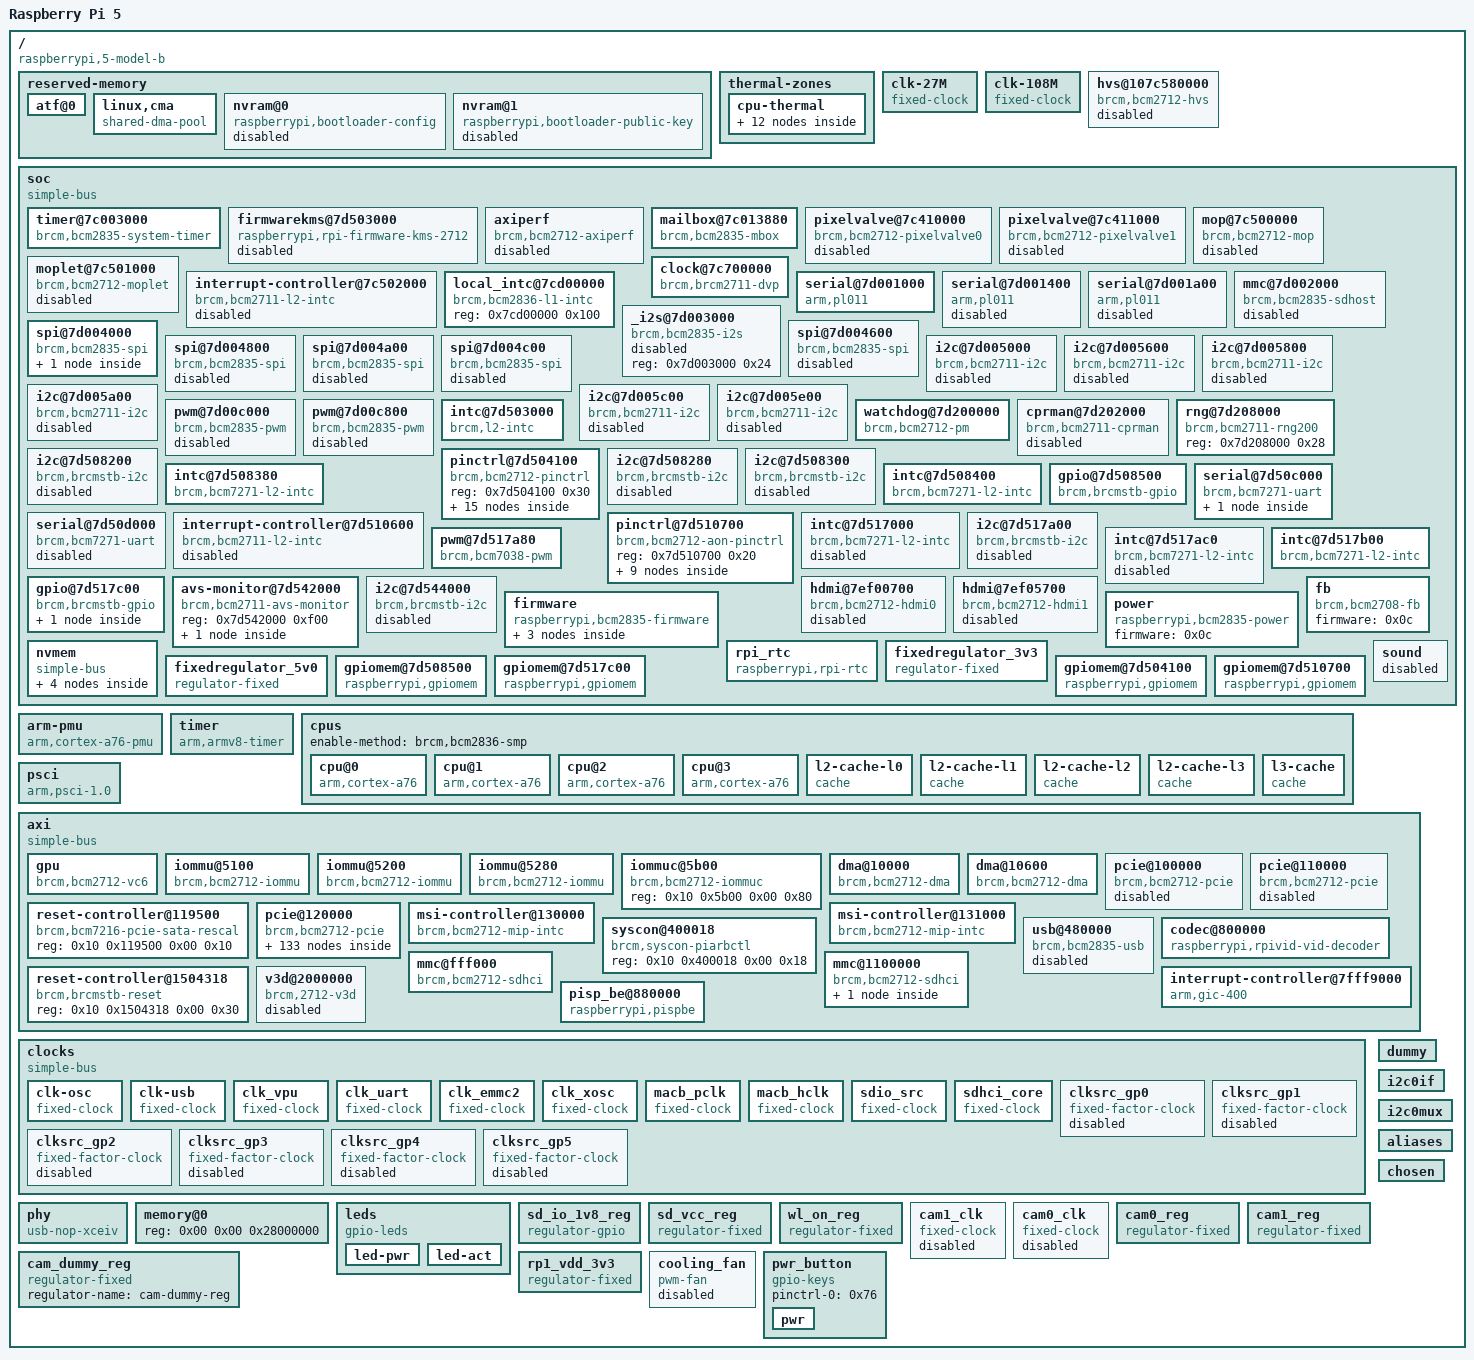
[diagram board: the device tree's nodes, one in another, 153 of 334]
/dts-v1/;

/ {
	compatible = "raspberrypi,5-model-b", "brcm,bcm2712";
	model = "Raspberry Pi 5";
	#address-cells = <0x02>;
	#size-cells = <0x01>;
	interrupt-parent = <0x01>;

	reserved-memory {
		#address-cells = <0x02>;
		#size-cells = <0x01>;
		ranges;
		phandle = <0x77>;

		atf@0 {
			reg = <0x00 0x00 0x80000>;
			no-map;
		};

		linux,cma {
			compatible = "shared-dma-pool";
			size = <0x4000000>;
			reusable;
			linux,cma-default;
			alloc-ranges = <0x00 0x00 0x40000000>;
			phandle = <0x78>;
		};

		nvram@0 {
			compatible = "raspberrypi,bootloader-config", "nvmem-rmem";
			#address-cells = <0x01>;
			#size-cells = <0x01>;
			reg = <0x00 0x00 0x00>;
			no-map;
			status = "disabled";
			phandle = <0x79>;
		};

		nvram@1 {
			compatible = "raspberrypi,bootloader-public-key", "nvmem-rmem";
			#address-cells = <0x01>;
			#size-cells = <0x01>;
			reg = <0x00 0x00 0x00>;
			no-map;
			status = "disabled";
			phandle = <0x7a>;
		};
	};

	thermal-zones {

		cpu-thermal {
			polling-delay-passive = <0x3e8>;
			polling-delay = <0x3e8>;
			coefficients = <0xfffffdda 0x6ddd0>;
			thermal-sensors = <0x02>;
			phandle = <0x7b>;

			trips {
				phandle = <0x7c>;

				cpu-crit {
					temperature = <0x1adb0>;
					hysteresis = <0x00>;
					type = "critical";
					phandle = <0x08>;
				};

				cpu-tepid {
					temperature = <0xc350>;
					hysteresis = <0x1388>;
					type = "active";
					phandle = <0x03>;
				};

				cpu-warm {
					temperature = <0xea60>;
					hysteresis = <0x1388>;
					type = "active";
					phandle = <0x05>;
				};

				cpu-hot {
					temperature = <0x107ac>;
					hysteresis = <0x1388>;
					type = "active";
					phandle = <0x06>;
				};

				cpu-vhot {
					temperature = <0x124f8>;
					hysteresis = <0x1388>;
					type = "active";
					phandle = <0x07>;
				};
			};

			cooling-maps {
				phandle = <0x7d>;

				tepid {
					trip = <0x03>;
					cooling-device = <0x04 0x01 0x01>;
				};

				warm {
					trip = <0x05>;
					cooling-device = <0x04 0x02 0x02>;
				};

				hot {
					trip = <0x06>;
					cooling-device = <0x04 0x03 0x03>;
				};

				vhot {
					trip = <0x07>;
					cooling-device = <0x04 0x04 0x04>;
				};

				melt {
					trip = <0x08>;
					cooling-device = <0x04 0x04 0x04>;
				};
			};
		};
	};

	clk-27M {
		#clock-cells = <0x00>;
		compatible = "fixed-clock";
		clock-frequency = <0x19bfcc0>;
		clock-output-names = "27MHz-clock";
		phandle = <0x1b>;
	};

	clk-108M {
		#clock-cells = <0x00>;
		compatible = "fixed-clock";
		clock-frequency = <0x66ff300>;
		clock-output-names = "108MHz-clock";
		phandle = <0x0d>;
	};

	hvs@107c580000 {
		compatible = "brcm,bcm2712-hvs";
		reg = <0x10 0x7c580000 0x1a000>;
		interrupt-parent = <0x09>;
		interrupts = <0x02 0x09 0x10>;
		interrupt-names = "ch0-eof", "ch1-eof", "ch2-eof";
		status = "disabled";
		clocks = <0x0a 0x04 0x0a 0x10>;
		clock-names = "core", "disp";
		phandle = <0x7e>;
	};

	soc {
		compatible = "simple-bus";
		#address-cells = <0x01>;
		#size-cells = <0x01>;
		ranges = <0x7c000000 0x10 0x7c000000 0x4000000>;
		dma-ranges = <0xc0000000 0x00 0x00 0x40000000 0x7c000000 0x10 0x7c000000 0x4000000>;
		phandle = <0x7f>;

		timer@7c003000 {
			compatible = "brcm,bcm2835-system-timer";
			reg = <0x7c003000 0x1000>;
			interrupts = <0x00 0x40 0x04 0x00 0x41 0x04 0x00 0x42 0x04 0x00 0x43 0x04>;
			clock-frequency = <0xf4240>;
			phandle = <0x80>;
		};

		firmwarekms@7d503000 {
			compatible = "raspberrypi,rpi-firmware-kms-2712";
			reg = <0x7d503000 0x18>;
			interrupt-parent = <0x0b>;
			interrupts = <0x13>;
			brcm,firmware = <0x0c>;
			status = "disabled";
			phandle = <0x81>;
		};

		axiperf {
			compatible = "brcm,bcm2712-axiperf";
			reg = <0x7c012800 0x100 0x7e000000 0x100>;
			firmware = <0x0c>;
			status = "disabled";
			phandle = <0x5f>;
		};

		mailbox@7c013880 {
			compatible = "brcm,bcm2835-mbox";
			reg = <0x7c013880 0x40>;
			interrupts = <0x00 0x21 0x04>;
			#mbox-cells = <0x00>;
			phandle = <0x21>;
		};

		pixelvalve@7c410000 {
			compatible = "brcm,bcm2712-pixelvalve0";
			reg = <0x7c410000 0x100>;
			interrupts = <0x00 0x65 0x04>;
			status = "disabled";
			phandle = <0x82>;
		};

		pixelvalve@7c411000 {
			compatible = "brcm,bcm2712-pixelvalve1";
			reg = <0x7c411000 0x100>;
			interrupts = <0x00 0x6e 0x04>;
			status = "disabled";
			phandle = <0x83>;
		};

		mop@7c500000 {
			compatible = "brcm,bcm2712-mop";
			reg = <0x7c500000 0x28>;
			interrupt-parent = <0x09>;
			interrupts = <0x01>;
			status = "disabled";
			phandle = <0x84>;
		};

		moplet@7c501000 {
			compatible = "brcm,bcm2712-moplet";
			reg = <0x7c501000 0x20>;
			interrupt-parent = <0x09>;
			interrupts = <0x00>;
			status = "disabled";
			phandle = <0x85>;
		};

		interrupt-controller@7c502000 {
			compatible = "brcm,bcm2711-l2-intc", "brcm,l2-intc";
			reg = <0x7c502000 0x30>;
			interrupts = <0x00 0x61 0x04>;
			interrupt-controller;
			#interrupt-cells = <0x01>;
			status = "disabled";
			phandle = <0x09>;
		};

		clock@7c700000 {
			compatible = "brcm,brcm2711-dvp";
			reg = <0x7c700000 0x10>;
			clocks = <0x0d>;
			#clock-cells = <0x01>;
			#reset-cells = <0x01>;
			phandle = <0x1d>;
		};

		local_intc@7cd00000 {
			compatible = "brcm,bcm2836-l1-intc";
			reg = <0x7cd00000 0x100>;
			phandle = <0x86>;
		};

		serial@7d001000 {
			compatible = "arm,pl011", "arm,primecell";
			reg = <0x7d001000 0x200>;
			interrupts = <0x00 0x79 0x04>;
			clocks = <0x0e 0x0f>;
			clock-names = "uartclk", "apb_pclk";
			arm,primecell-periphid = <0x241011>;
			status = "okay";
			phandle = <0x87>;
		};

		serial@7d001400 {
			compatible = "arm,pl011", "arm,primecell";
			reg = <0x7d001400 0x200>;
			interrupts = <0x00 0x79 0x04>;
			clocks = <0x0e 0x0f>;
			clock-names = "uartclk", "apb_pclk";
			arm,primecell-periphid = <0x241011>;
			status = "disabled";
			phandle = <0x88>;
		};

		serial@7d001a00 {
			compatible = "arm,pl011", "arm,primecell";
			reg = <0x7d001a00 0x200>;
			interrupts = <0x00 0x79 0x04>;
			clocks = <0x0e 0x0f>;
			clock-names = "uartclk", "apb_pclk";
			arm,primecell-periphid = <0x241011>;
			status = "disabled";
			phandle = <0x89>;
		};

		mmc@7d002000 {
			compatible = "brcm,bcm2835-sdhost";
			reg = <0x7d002000 0x100>;
			clocks = <0x0f>;
			status = "disabled";
			phandle = <0x8a>;
		};

		_i2s@7d003000 {
			compatible = "brcm,bcm2835-i2s";
			reg = <0x7d003000 0x24>;
			status = "disabled";
			phandle = <0x8b>;
		};

		spi@7d004000 {
			compatible = "brcm,bcm2835-spi";
			reg = <0x7d004000 0x200>;
			interrupts = <0x00 0x76 0x04>;
			clocks = <0x0f>;
			num-cs = <0x01>;
			#address-cells = <0x01>;
			#size-cells = <0x00>;
			status = "okay";
			dmas = <0x10 0x06 0x10 0x07>;
			dma-names = "tx", "rx";
			pinctrl-names = "default";
			cs-gpios = <0x11 0x01 0x01>;
			pinctrl-0 = <0x12 0x13>;
			phandle = <0x8c>;

			spidev@0 {
				compatible = "spidev";
				reg = <0x00>;
				#address-cells = <0x01>;
				#size-cells = <0x00>;
				spi-max-frequency = <0x1312d00>;
				status = "okay";
				phandle = <0x8d>;
			};
		};

		spi@7d004600 {
			compatible = "brcm,bcm2835-spi";
			reg = <0x7d004600 0x200>;
			interrupts = <0x00 0x76 0x04>;
			clocks = <0x0f>;
			#address-cells = <0x01>;
			#size-cells = <0x00>;
			status = "disabled";
			phandle = <0x8e>;
		};

		spi@7d004800 {
			compatible = "brcm,bcm2835-spi";
			reg = <0x7d004800 0x200>;
			interrupts = <0x00 0x76 0x04>;
			clocks = <0x0f>;
			#address-cells = <0x01>;
			#size-cells = <0x00>;
			status = "disabled";
			phandle = <0x8f>;
		};

		spi@7d004a00 {
			compatible = "brcm,bcm2835-spi";
			reg = <0x7d004a00 0x200>;
			interrupts = <0x00 0x76 0x04>;
			clocks = <0x0f>;
			#address-cells = <0x01>;
			#size-cells = <0x00>;
			status = "disabled";
			phandle = <0x90>;
		};

		spi@7d004c00 {
			compatible = "brcm,bcm2835-spi";
			reg = <0x7d004c00 0x200>;
			interrupts = <0x00 0x76 0x04>;
			clocks = <0x0f>;
			#address-cells = <0x01>;
			#size-cells = <0x00>;
			status = "disabled";
			phandle = <0x91>;
		};

		i2c@7d005000 {
			compatible = "brcm,bcm2711-i2c", "brcm,bcm2835-i2c";
			reg = <0x7d005000 0x20>;
			interrupts = <0x00 0x75 0x04>;
			clocks = <0x0f>;
			#address-cells = <0x01>;
			#size-cells = <0x00>;
			status = "disabled";
			phandle = <0x92>;
		};

		i2c@7d005600 {
			compatible = "brcm,bcm2711-i2c", "brcm,bcm2835-i2c";
			reg = <0x7d005600 0x20>;
			interrupts = <0x00 0x75 0x04>;
			clocks = <0x0f>;
			#address-cells = <0x01>;
			#size-cells = <0x00>;
			status = "disabled";
			clock-frequency = <0x61a80>;
			pinctrl-0 = <0x14>;
			pinctrl-names = "default";
			phandle = <0x93>;
		};

		i2c@7d005800 {
			compatible = "brcm,bcm2711-i2c", "brcm,bcm2835-i2c";
			reg = <0x7d005800 0x20>;
			interrupts = <0x00 0x75 0x04>;
			clocks = <0x0f>;
			#address-cells = <0x01>;
			#size-cells = <0x00>;
			status = "disabled";
			phandle = <0x94>;
		};

		i2c@7d005a00 {
			compatible = "brcm,bcm2711-i2c", "brcm,bcm2835-i2c";
			reg = <0x7d005a00 0x20>;
			interrupts = <0x00 0x75 0x04>;
			clocks = <0x0f>;
			#address-cells = <0x01>;
			#size-cells = <0x00>;
			status = "disabled";
			phandle = <0x95>;
		};

		i2c@7d005c00 {
			compatible = "brcm,bcm2711-i2c", "brcm,bcm2835-i2c";
			reg = <0x7d005c00 0x20>;
			interrupts = <0x00 0x75 0x04>;
			clocks = <0x0f>;
			#address-cells = <0x01>;
			#size-cells = <0x00>;
			status = "disabled";
			phandle = <0x96>;
		};

		i2c@7d005e00 {
			compatible = "brcm,bcm2711-i2c", "brcm,bcm2835-i2c";
			reg = <0x7d005e00 0x20>;
			interrupts = <0x00 0x75 0x04>;
			clocks = <0x0f>;
			#address-cells = <0x01>;
			#size-cells = <0x00>;
			status = "disabled";
			phandle = <0x97>;
		};

		pwm@7d00c000 {
			compatible = "brcm,bcm2835-pwm";
			reg = <0x7d00c000 0x28>;
			assigned-clock-rates = <0x2faf080>;
			#pwm-cells = <0x03>;
			status = "disabled";
			phandle = <0x98>;
		};

		pwm@7d00c800 {
			compatible = "brcm,bcm2835-pwm";
			reg = <0x7d00c800 0x28>;
			assigned-clock-rates = <0x2faf080>;
			#pwm-cells = <0x03>;
			status = "disabled";
			phandle = <0x99>;
		};

		watchdog@7d200000 {
			compatible = "brcm,bcm2712-pm";
			reg = <0x7d200000 0x308>;
			reg-names = "pm";
			#power-domain-cells = <0x01>;
			#reset-cells = <0x01>;
			clock-names = "v3d", "peri_image", "h264", "isp";
			system-power-controller;
			phandle = <0x5c>;
		};

		cprman@7d202000 {
			compatible = "brcm,bcm2711-cprman";
			reg = "}  ", "", "", " ";
			#clock-cells = <0x01>;
			clocks = <0x15>;
			status = "disabled";
			phandle = <0x9a>;
		};

		rng@7d208000 {
			compatible = "brcm,bcm2711-rng200";
			reg = <0x7d208000 0x28>;
			status = "okay";
			phandle = <0x6d>;
		};

		intc@7d503000 {
			compatible = "brcm,l2-intc";
			reg = <0x7d503000 0x18>;
			interrupts = <0x00 0xee 0x04>;
			interrupt-controller;
			#interrupt-cells = <0x01>;
			phandle = <0x0b>;
		};

		pinctrl@7d504100 {
			compatible = "brcm,bcm2712-pinctrl";
			reg = <0x7d504100 0x30>;
			phandle = <0x9b>;

			uarta_24_pins {
				phandle = <0x18>;

				pin_rts {
					function = "uart0";
					pins = "gpio24";
					bias-disable;
				};

				pin_cts {
					function = "uart0";
					pins = "gpio25";
					bias-pull-up;
				};

				pin_txd {
					function = "uart0";
					pins = "gpio26";
					bias-disable;
				};

				pin_rxd {
					function = "uart0";
					pins = "gpio27";
					bias-pull-up;
				};
			};

			sdio2_30_pins {
				phandle = <0x5a>;

				pin_clk {
					function = "sd2";
					pins = "gpio30";
					bias-disable;
				};

				pin_cmd {
					function = "sd2";
					pins = "gpio31";
					bias-pull-up;
				};

				pins_dat {
					function = "sd2";
					pins = "gpio32", "gpio33", "gpio34", "gpio35";
					bias-pull-up;
				};
			};

			pwr_button_pins {
				function = "gpio";
				pins = "gpio20";
				bias-pull-up;
				phandle = <0x76>;
			};

			wl_on_pins {
				function = "gpio";
				pins = "gpio28";
				phandle = <0x5d>;
			};

			bt_shutdown_pins {
				function = "gpio";
				pins = "gpio29";
				phandle = <0x19>;
			};

			emmc_sd_pulls {
				pins = "emmc_cmd", "emmc_dat0", "emmc_dat1", "emmc_dat2", "emmc_dat3";
				bias-pull-up;
				phandle = <0x55>;
			};

			spi10_gpio2 {
				function = "vc_spi0";
				pins = "gpio2", "gpio3", "gpio4";
				bias-disable;
				phandle = <0x12>;
			};

			spi10_cs_gpio1 {
				function = "gpio";
				pins = "gpio1";
				bias-pull-up;
				phandle = <0x13>;
			};
		};

		i2c@7d508200 {
			compatible = "brcm,brcmstb-i2c";
			reg = <0x7d508200 0x58>;
			interrupt-parent = <0x16>;
			interrupts = <0x01>;
			clock-frequency = <0x17cdc>;
			#address-cells = <0x01>;
			#size-cells = <0x00>;
			status = "disabled";
			phandle = <0x1f>;
		};

		i2c@7d508280 {
			compatible = "brcm,brcmstb-i2c";
			reg = <0x7d508280 0x58>;
			interrupt-parent = <0x16>;
			interrupts = <0x02>;
			clock-frequency = <0x17cdc>;
			#address-cells = <0x01>;
			#size-cells = <0x00>;
			status = "disabled";
			phandle = <0x20>;
		};

		i2c@7d508300 {
			compatible = "brcm,brcmstb-i2c";
			reg = <0x7d508300 0x58>;
			interrupt-parent = <0x16>;
			interrupts = <0x00>;
			clock-frequency = <0x30d40>;
			#address-cells = <0x01>;
			#size-cells = <0x00>;
			status = "disabled";
			phandle = <0x9c>;
		};

		intc@7d508380 {
			compatible = "brcm,bcm7271-l2-intc";
			reg = <0x7d508380 0x10>;
			interrupts = <0x00 0xf2 0x04>;
			interrupt-controller;
			#interrupt-cells = <0x01>;
			phandle = <0x16>;
		};

		intc@7d508400 {
			compatible = "brcm,bcm7271-l2-intc";
			reg = <0x7d508400 0x10>;
			interrupts = <0x00 0xf4 0x04>;
			interrupt-controller;
			#interrupt-cells = <0x01>;
			phandle = <0x17>;
		};

		gpio@7d508500 {
			compatible = "brcm,brcmstb-gpio";
			reg = <0x7d508500 0x40>;
			interrupt-parent = <0x17>;
			interrupts = <0x00>;
			gpio-controller;
			#gpio-cells = <0x02>;
			interrupt-controller;
			#interrupt-cells = <0x02>;
			brcm,gpio-bank-widths = <0x20 0x04>;
			brcm,gpio-direct;
			gpio-line-names = "-", "2712_BOOT_CS_N", "2712_BOOT_MISO", "2712_BOOT_MOSI", "2712_BOOT_SCLK", "-", "-", "-", "-", "-", "-", "-", "-", "-", "PCIE_SDA", "PCIE_SCL", "-", "-", "-", "-", "PWR_GPIO", "2712_G21_FS", "-", "-", "BT_RTS", "BT_CTS", "BT_TXD", "BT_RXD", "WL_ON", "BT_ON", "WIFI_SDIO_CLK", "WIFI_SDIO_CMD", "WIFI_SDIO_D0", "WIFI_SDIO_D1", "WIFI_SDIO_D2", "WIFI_SDIO_D3";
			phandle = <0x11>;
		};

		serial@7d50c000 {
			compatible = "brcm,bcm7271-uart";
			reg = <0x7d50c000 0x20>;
			reg-names = "uart";
			reg-shift = <0x02>;
			reg-io-width = <0x04>;
			interrupts = <0x00 0x114 0x04>;
			skip-init;
			status = "okay";
			uart-has-rtscts;
			auto-flow-control;
			clock-frequency = <0x5b8d800>;
			pinctrl-0 = <0x18 0x19>;
			pinctrl-names = "default";
			phandle = <0x9d>;

			bluetooth {
				compatible = "brcm,bcm43438-bt";
				max-speed = <0x2dc6c0>;
				shutdown-gpios = <0x11 0x1d 0x00>;
				local-bd-address = [00 00 00 00 00 00];
				phandle = <0x60>;
			};
		};

		serial@7d50d000 {
			compatible = "brcm,bcm7271-uart";
			reg = <0x7d50d000 0x20>;
			reg-names = "uart";
			reg-shift = <0x02>;
			reg-io-width = <0x04>;
			interrupts = <0x00 0x115 0x04>;
			skip-init;
			status = "disabled";
			phandle = <0x9e>;
		};

		interrupt-controller@7d510600 {
			compatible = "brcm,bcm2711-l2-intc", "brcm,l2-intc";
			reg = <0x7d510600 0x30>;
			interrupts = <0x00 0xef 0x04>;
			interrupt-controller;
			#interrupt-cells = <0x01>;
			status = "disabled";
			phandle = <0x1e>;
		};

		pinctrl@7d510700 {
			compatible = "brcm,bcm2712-aon-pinctrl";
			reg = <0x7d510700 0x20>;
			phandle = <0x9f>;

			i2c3_m4_agpio0_pins {
				function = "vc_i2c3";
				pins = "aon_gpio0", "aon_gpio1";
				bias-pull-up;
				phandle = <0x14>;
			};

			bsc_m1_agpio13_pins {
				function = "bsc_m1";
				pins = "aon_gpio13", "aon_gpio14";
				bias-pull-up;
				phandle = <0xa0>;
			};

			bsc_pmu_sgpio4_pins {
				function = "avs_pmu_bsc";
				pins = "aon_sgpio4", "aon_sgpio5";
				phandle = <0xa1>;
			};

			bsc_m2_sgpio4_pins {
				function = "bsc_m2";
				pins = "aon_sgpio4", "aon_sgpio5";
				phandle = <0xa2>;
			};

			pwm_aon_agpio1_pins {
				function = "aon_pwm";
				pins = "aon_gpio1", "aon_gpio2";
				phandle = <0xa3>;
			};

			pwm_aon_agpio4_pins {
				function = "vc_pwm0";
				pins = "aon_gpio4", "aon_gpio5";
				phandle = <0xa4>;
			};

			pwm_aon_agpio7_pins {
				function = "aon_pwm";
				pins = "aon_gpio7", "aon_gpio9";
				phandle = <0xa5>;
			};

			emmc_aon_cd_pins {
				function = "sd_card_g";
				pins = "aon_gpio5";
				bias-pull-up;
				phandle = <0x56>;
			};

			aon_pwm_1pin {
				function = "aon_pwm";
				pins = "aon_gpio9";
				phandle = <0xa6>;
			};
		};

		intc@7d517000 {
			compatible = "brcm,bcm7271-l2-intc";
			reg = <0x7d517000 0x10>;
			interrupts = <0x00 0xf7 0x04>;
			interrupt-controller;
			#interrupt-cells = <0x01>;
			status = "disabled";
		};

		i2c@7d517a00 {
			compatible = "brcm,brcmstb-i2c";
			reg = <0x7d517a00 0x58>;
			interrupt-parent = <0x1a>;
			interrupts = <0x00>;
			clock-frequency = <0x30d40>;
			#address-cells = <0x01>;
			#size-cells = <0x00>;
			status = "disabled";
			phandle = <0xa7>;
		};

		pwm@7d517a80 {
			compatible = "brcm,bcm7038-pwm";
			reg = <0x7d517a80 0x28>;
			#pwm-cells = <0x03>;
			clocks = <0x1b>;
			phandle = <0xa8>;
		};

		intc@7d517ac0 {
			compatible = "brcm,bcm7271-l2-intc";
			reg = <0x7d517ac0 0x10>;
			interrupts = <0x00 0xf5 0x04>;
			interrupt-controller;
			#interrupt-cells = <0x01>;
			status = "disabled";
			phandle = <0x1c>;
		};

		intc@7d517b00 {
			compatible = "brcm,bcm7271-l2-intc";
			reg = <0x7d517b00 0x10>;
			interrupts = <0x00 0xf3 0x04>;
			interrupt-controller;
			#interrupt-cells = <0x01>;
			phandle = <0x1a>;
		};

		gpio@7d517c00 {
			compatible = "brcm,brcmstb-gpio";
			reg = <0x7d517c00 0x40>;
			interrupt-parent = <0x1c>;
			interrupts = <0x00>;
			gpio-controller;
			#gpio-cells = <0x02>;
			#interrupt-cells = <0x02>;
			brcm,gpio-bank-widths = <0x11 0x06>;
			brcm,gpio-direct;
			gpio-line-names = "RP1_SDA", "RP1_SCL", "RP1_RUN", "SD_IOVDD_SEL", "SD_PWR_ON", "SD_CDET_N", "SD_FLG_N", "-", "2712_WAKE", "2712_STAT_LED", "-", "-", "PMIC_INT", "UART_TX_FS", "UART_RX_FS", "-", "-", "", "", "", "", "", "", "", "", "", "", "", "", "", "", "", "HDMI0_SCL", "HDMI0_SDA", "HDMI1_SCL", "HDMI1_SDA", "PMIC_SCL", "PMIC_SDA";
			phandle = <0x59>;

			rp1_run_hog {
				gpio-hog;
				gpios = <0x02 0x00>;
				output-high;
				line-name = "RP1 RUN pin";
			};
		};

		avs-monitor@7d542000 {
			compatible = "brcm,bcm2711-avs-monitor", "syscon", "simple-mfd";
			reg = <0x7d542000 0xf00>;
			status = "okay";
			phandle = <0xa9>;

			thermal {
				compatible = "brcm,bcm2711-thermal";
				#thermal-sensor-cells = <0x00>;
				phandle = <0x02>;
			};
		};

		i2c@7d544000 {
			compatible = "brcm,brcmstb-i2c";
			reg = <0x7d544000 0x58>;
			interrupt-parent = <0x1a>;
			interrupts = <0x01>;
			clock-frequency = <0x30d40>;
			status = "disabled";
			phandle = <0xaa>;
		};

		hdmi@7ef00700 {
			compatible = "brcm,bcm2712-hdmi0";
			reg = <0x7c701400 0x300 0x7c701000 0x200 0x7c701d00 0x300 0x7c702000 0x80 0x7c703800 0x200 0x7c704000 0x800 0x7c700100 0x80 0x7d510800 0x100 0x7c720000 0x100>;
			reg-names = "hdmi", "dvp", "phy", "rm", "packet", "metadata", "csc", "cec", "hd";
			resets = <0x1d 0x01>;
			interrupt-parent = <0x1e>;
			interrupts = <0x01 0x02 0x03 0x07 0x08>;
			interrupt-names = "cec-tx", "cec-rx", "cec-low", "hpd-connected", "hpd-removed";
			ddc = <0x1f>;
			dmas = <0x10 0x41fa000a>;
			dma-names = "audio-rx";
			status = "disabled";
			clocks = <0x0a 0x0d 0x0a 0x0e 0x1d 0x00 0x1b>;
			clock-names = "hdmi", "bvb", "audio", "cec";
			phandle = <0xab>;
		};

		hdmi@7ef05700 {
			compatible = "brcm,bcm2712-hdmi1";
			reg = <0x7c706400 0x300 0x7c706000 0x200 0x7c706d00 0x300 0x7c707000 0x80 0x7c708800 0x200 0x7c709000 0x800 0x7c700180 0x80 0x7d511000 0x100 0x7c720000 0x100>;
			reg-names = "hdmi", "dvp", "phy", "rm", "packet", "metadata", "csc", "cec", "hd";
			ddc = <0x20>;
			resets = <0x1d 0x02>;
			interrupt-parent = <0x1e>;
			interrupts = <0x0b 0x0c 0x0d 0x0e 0x0f>;
			interrupt-names = "cec-tx", "cec-rx", "cec-low", "hpd-connected", "hpd-removed";
			dmas = <0x10 0x41fa0011>;
			dma-names = "audio-rx";
			status = "disabled";
			clocks = <0x0a 0x0d 0x0a 0x0e 0x1d 0x01 0x1b>;
			clock-names = "hdmi", "bvb", "audio", "cec";
			phandle = <0xac>;
		};

		firmware {
			compatible = "raspberrypi,bcm2835-firmware", "simple-mfd";
			#address-cells = <0x01>;
			#size-cells = <0x01>;
			mboxes = <0x21>;
			dma-ranges;
			phandle = <0x0c>;

			clocks {
				compatible = "raspberrypi,firmware-clocks";
				#clock-cells = <0x01>;
				phandle = <0x0a>;
			};

			reset {
				compatible = "raspberrypi,firmware-reset";
				#reset-cells = <0x01>;
				phandle = <0xad>;
			};

			vcio {
				compatible = "raspberrypi,vcio";
				phandle = <0xae>;
			};
		};

		power {
			compatible = "raspberrypi,bcm2835-power";
			firmware = <0x0c>;
			#power-domain-cells = <0x01>;
			phandle = <0x52>;
		};

		fb {
			compatible = "brcm,bcm2708-fb";
			firmware = <0x0c>;
			status = "okay";
			phandle = <0xaf>;
		};

		rpi_rtc {
			compatible = "raspberrypi,rpi-rtc";
			firmware = <0x0c>;
			status = "okay";
			trickle-charge-microvolt = <0x00>;
			phandle = <0x6e>;
		};

		nvmem {
			compatible = "simple-bus";
			#address-cells = <0x01>;
			#size-cells = <0x01>;

			nvmem_otp {
				compatible = "raspberrypi,rpi-otp";
				firmware = <0x0c>;
				reg = <0x00 0xc0>;
				status = "okay";
				phandle = <0xb0>;
			};

			nvmem_cust {
				compatible = "raspberrypi,rpi-otp";
				firmware = <0x0c>;
				reg = <0x01 0x08>;
				status = "okay";
				phandle = <0x69>;
			};

			nvmem_mac {
				compatible = "raspberrypi,rpi-otp";
				firmware = <0x0c>;
				reg = <0x02 0x06>;
				status = "okay";
				phandle = <0x6a>;
			};

			nvmem_priv {
				compatible = "raspberrypi,rpi-otp";
				firmware = <0x0c>;
				reg = <0x03 0x10>;
				status = "okay";
				phandle = <0x6b>;
			};
		};

		fixedregulator_3v3 {
			compatible = "regulator-fixed";
			regulator-always-on;
			regulator-max-microvolt = <0x325aa0>;
			regulator-min-microvolt = <0x325aa0>;
			regulator-name = "3v3";
			phandle = <0xb1>;
		};

		fixedregulator_5v0 {
			compatible = "regulator-fixed";
			regulator-always-on;
			regulator-max-microvolt = <0x4c4b40>;
			regulator-min-microvolt = <0x4c4b40>;
			regulator-name = "5v0";
			phandle = <0xb2>;
		};

		gpiomem@7d508500 {
			compatible = "raspberrypi,gpiomem";
			reg = <0x7d508500 0x40>;
			chardev-name = "gpiomem1";
		};

		gpiomem@7d517c00 {
			compatible = "raspberrypi,gpiomem";
			reg = <0x7d517c00 0x40>;
			chardev-name = "gpiomem2";
		};

		gpiomem@7d504100 {
			compatible = "raspberrypi,gpiomem";
			reg = <0x7d504100 0x20>;
			chardev-name = "gpiomem3";
		};

		gpiomem@7d510700 {
			compatible = "raspberrypi,gpiomem";
			reg = <0x7d510700 0x20>;
			chardev-name = "gpiomem4";
		};

		sound {
			status = "disabled";
			phandle = <0xb3>;
		};
	};

	arm-pmu {
		compatible = "arm,cortex-a76-pmu";
		interrupts = <0x00 0x10 0x04 0x00 0x11 0x04 0x00 0x12 0x04 0x00 0x13 0x04>;
		interrupt-affinity = <0x22 0x23 0x24 0x25>;
	};

	timer {
		compatible = "arm,armv8-timer";
		interrupts = <0x01 0x0d 0xf08 0x01 0x0e 0xf08 0x01 0x0b 0xf08 0x01 0x0a 0xf08>;
		arm,cpu-registers-not-fw-configured;
	};

	cpus {
		#address-cells = <0x01>;
		#size-cells = <0x00>;
		enable-method = "brcm,bcm2836-smp";
		phandle = <0xb4>;

		cpu@0 {
			device_type = "cpu";
			compatible = "arm,cortex-a76";
			reg = <0x00>;
			enable-method = "psci";
			d-cache-size = <0x10000>;
			d-cache-line-size = <0x40>;
			d-cache-sets = <0x100>;
			i-cache-size = <0x10000>;
			i-cache-line-size = <0x40>;
			i-cache-sets = <0x100>;
			next-level-cache = <0x26>;
			phandle = <0x22>;
		};

		cpu@1 {
			device_type = "cpu";
			compatible = "arm,cortex-a76";
			reg = <0x100>;
			enable-method = "psci";
			d-cache-size = <0x10000>;
			d-cache-line-size = <0x40>;
			d-cache-sets = <0x100>;
			i-cache-size = <0x10000>;
			i-cache-line-size = <0x40>;
			i-cache-sets = <0x100>;
			next-level-cache = <0x27>;
			phandle = <0x23>;
		};

		cpu@2 {
			device_type = "cpu";
			compatible = "arm,cortex-a76";
			reg = <0x200>;
			enable-method = "psci";
			d-cache-size = <0x10000>;
			d-cache-line-size = <0x40>;
			d-cache-sets = <0x100>;
			i-cache-size = <0x10000>;
			i-cache-line-size = <0x40>;
			i-cache-sets = <0x100>;
			next-level-cache = <0x28>;
			phandle = <0x24>;
		};

		cpu@3 {
			device_type = "cpu";
			compatible = "arm,cortex-a76";
			reg = <0x300>;
			enable-method = "psci";
			d-cache-size = <0x10000>;
			d-cache-line-size = <0x40>;
			d-cache-sets = <0x100>;
			i-cache-size = <0x10000>;
			i-cache-line-size = <0x40>;
			i-cache-sets = <0x100>;
			next-level-cache = <0x29>;
			phandle = <0x25>;
		};

		l2-cache-l0 {
			compatible = "cache";
			cache-size = <0x80000>;
			cache-line-size = <0x80>;
			cache-sets = <0x400>;
			cache-level = <0x02>;
			cache-unified;
			next-level-cache = <0x2a>;
			phandle = <0x26>;
		};

		l2-cache-l1 {
			compatible = "cache";
			cache-size = <0x80000>;
			cache-line-size = <0x80>;
			cache-sets = <0x400>;
			cache-level = <0x02>;
			cache-unified;
			next-level-cache = <0x2a>;
			phandle = <0x27>;
		};

		l2-cache-l2 {
			compatible = "cache";
			cache-size = <0x80000>;
			cache-line-size = <0x80>;
			cache-sets = <0x400>;
			cache-level = <0x02>;
			cache-unified;
			next-level-cache = <0x2a>;
			phandle = <0x28>;
		};

		l2-cache-l3 {
			compatible = "cache";
			cache-size = <0x80000>;
			cache-line-size = <0x80>;
			cache-sets = <0x400>;
			cache-level = <0x02>;
			cache-unified;
			next-level-cache = <0x2a>;
			phandle = <0x29>;
		};

		l3-cache {
			compatible = "cache";
			cache-size = <0x200000>;
			cache-line-size = <0x40>;
			cache-sets = <0x800>;
			cache-level = <0x03>;
			phandle = <0x2a>;
		};
	};

	psci {
		method = "smc";
		compatible = "arm,psci-1.0", "arm,psci-0.2", "arm,psci";
		cpu_on = <0xc4000003>;
		cpu_suspend = <0xc4000001>;
		cpu_off = <0x84000002>;
	};

	axi {
		compatible = "simple-bus";
		#address-cells = <0x02>;
		#size-cells = <0x02>;
		ranges = <0x00 0x00 0x00 0x00 0x10 0x00 0x10 0x00 0x10 0x00 0x01 0x00 0x14 0x00 0x14 0x00 0x04 0x00 0x18 0x00 0x18 0x00 0x04 0x00 0x1c 0x00 0x1c 0x00 0x04 0x00>;
		dma-ranges = <0x00 0x00 0x00 0x00 0x10 0x00 0x10 0x00 0x10 0x00 0x01 0x00 0x14 0x00 0x14 0x00 0x04 0x00 0x18 0x00 0x18 0x00 0x04 0x00 0x1c 0x00 0x1c 0x00 0x04 0x00>;
		phandle = <0xb5>;

		gpu {
			compatible = "brcm,bcm2712-vc6";
			phandle = <0xb6>;
		};

		iommu@5100 {
			compatible = "brcm,bcm2712-iommu";
			reg = <0x10 0x5100 0x00 0x80>;
			cache = <0x2b>;
			#iommu-cells = <0x00>;
			phandle = <0x53>;
		};

		iommu@5200 {
			compatible = "brcm,bcm2712-iommu";
			reg = <0x10 0x5200 0x00 0x80>;
			cache = <0x2b>;
			#iommu-cells = <0x00>;
			#interconnect-cells = <0x00>;
			phandle = <0xb7>;
		};

		iommu@5280 {
			compatible = "brcm,bcm2712-iommu";
			reg = <0x10 0x5280 0x00 0x80>;
			cache = <0x2b>;
			#iommu-cells = <0x00>;
			dma-iova-offset = <0x10 0x00>;
			phandle = <0x4c>;
		};

		iommuc@5b00 {
			compatible = "brcm,bcm2712-iommuc";
			reg = <0x10 0x5b00 0x00 0x80>;
			phandle = <0x2b>;
		};

		dma@10000 {
			compatible = "brcm,bcm2712-dma";
			reg = <0x10 0x10000 0x00 0x600>;
			interrupts = <0x00 0x50 0x04 0x00 0x51 0x04 0x00 0x52 0x04 0x00 0x53 0x04 0x00 0x54 0x04 0x00 0x55 0x04>;
			interrupt-names = "dma0", "dma1", "dma2", "dma3", "dma4", "dma5";
			#dma-cells = <0x01>;
			brcm,dma-channel-mask = <0x3f>;
			phandle = <0xb8>;
		};

		dma@10600 {
			compatible = "brcm,bcm2712-dma";
			reg = <0x10 0x10600 0x00 0x600>;
			interrupts = <0x00 0x56 0x04 0x00 0x57 0x04 0x00 0x58 0x04 0x00 0x59 0x04 0x00 0x5a 0x04 0x00 0x5b 0x04>;
			interrupt-names = "dma6", "dma7", "dma8", "dma9", "dma10", "dma11";
			#dma-cells = <0x01>;
			brcm,dma-channel-mask = <0x7c0>;
			phandle = <0x10>;
		};

		pcie@100000 {
			compatible = "brcm,bcm2712-pcie";
			reg = <0x10 0x100000 0x00 0x9310>;
			device_type = "pci";
			max-link-speed = <0x02>;
			#address-cells = <0x03>;
			#interrupt-cells = <0x01>;
			#size-cells = <0x02>;
			interrupt-parent = <0x01>;
			interrupts = <0x00 0xd5 0x04 0x00 0xd6 0x04>;
			interrupt-names = "pcie", "msi";
			interrupt-map-mask = <0x00 0x00 0x00 0x07>;
			interrupt-map = <0x00 0x00 0x00 0x01 0x01 0x00 0xd1 0x04 0x00 0x00 0x00 0x02 0x01 0x00 0xd2 0x04 0x00 0x00 0x00 0x03 0x01 0x00 0xd3 0x04 0x00 0x00 0x00 0x04 0x01 0x00 0xd4 0x04>;
			resets = <0x2c 0x05 0x2c 0x2a 0x2d>;
			reset-names = "swinit", "bridge", "rescal";
			msi-controller;
			msi-parent = <0x2e>;
			ranges = <0x2000000 0x00 0x00 0x17 0x00 0x00 0xfffffffc 0x43000000 0x04 0x00 0x14 0x00 0x03 0x00>;
			dma-ranges = <0x43000000 0x10 0x00 0x00 0x00 0x10 0x00>;
			status = "disabled";
			phandle = <0x2e>;
		};

		pcie@110000 {
			compatible = "brcm,bcm2712-pcie";
			reg = <0x10 0x110000 0x00 0x9310>;
			device_type = "pci";
			max-link-speed = <0x02>;
			#address-cells = <0x03>;
			#interrupt-cells = <0x01>;
			#size-cells = <0x02>;
			interrupt-parent = <0x01>;
			interrupts = <0x00 0xdf 0x04 0x00 0xe0 0x04>;
			interrupt-names = "pcie", "msi";
			interrupt-map-mask = <0x00 0x00 0x00 0x07>;
			interrupt-map = <0x00 0x00 0x00 0x01 0x01 0x00 0xdb 0x04 0x00 0x00 0x00 0x02 0x01 0x00 0xdc 0x04 0x00 0x00 0x00 0x03 0x01 0x00 0xdd 0x04 0x00 0x00 0x00 0x04 0x01 0x00 0xde 0x04>;
			resets = <0x2c 0x07 0x2c 0x2b 0x2d>;
			reset-names = "swinit", "bridge", "rescal";
			msi-controller;
			msi-parent = <0x2f>;
			ranges = <0x2000000 0x00 0x80000000 0x1b 0x80000000 0x00 0x80000000 0x43000000 0x04 0x00 0x18 0x00 0x03 0x80000000>;
			dma-ranges = <0x3000000 0x10 0x00 0x00 0x00 0x10 0x00>;
			status = "disabled";
			brcm,vdm-qos-map = <0x33333333>;
			phandle = <0x68>;
		};

		reset-controller@119500 {
			compatible = "brcm,bcm7216-pcie-sata-rescal";
			reg = <0x10 0x119500 0x00 0x10>;
			#reset-cells = <0x00>;
			phandle = <0x2d>;
		};

		pcie@120000 {
			compatible = "brcm,bcm2712-pcie";
			reg = <0x10 0x120000 0x00 0x9310>;
			device_type = "pci";
			max-link-speed = <0x02>;
			#address-cells = <0x03>;
			#interrupt-cells = <0x01>;
			#size-cells = <0x02>;
			interrupt-parent = <0x01>;
			interrupts = <0x00 0xe9 0x04 0x00 0xea 0x04>;
			interrupt-names = "pcie", "msi";
			interrupt-map-mask = <0x00 0x00 0x00 0x07>;
			interrupt-map = <0x00 0x00 0x00 0x01 0x01 0x00 0xe5 0x04 0x00 0x00 0x00 0x02 0x01 0x00 0xe6 0x04 0x00 0x00 0x00 0x03 0x01 0x00 0xe7 0x04 0x00 0x00 0x00 0x04 0x01 0x00 0xe8 0x04>;
			resets = <0x2c 0x20 0x2c 0x2c 0x2d>;
			reset-names = "swinit", "bridge", "rescal";
			msi-controller;
			msi-parent = <0x30>;
			ranges = <0x2000000 0x00 0x00 0x1f 0x00 0x00 0xfffffffc 0x43000000 0x04 0x00 0x1c 0x00 0x03 0x00>;
			dma-ranges = <0x2000000 0x00 0x00 0x1f 0x00 0x00 0x400000 0x43000000 0x10 0x00 0x00 0x00 0x10 0x00>;
			status = "okay";
			brcm,enable-mps-rcb;
			brcm,vdm-qos-map = <0xbbaa9888>;
			aspm-no-l0s;
			phandle = <0xb9>;

			rp1 {
				compatible = "simple-bus";
				#address-cells = <0x02>;
				#size-cells = <0x02>;
				#interrupt-cells = <0x02>;
				interrupt-controller;
				interrupt-parent = <0x31>;
				ranges = <0xc0 0x40000000 0x2000000 0x00 0x00 0x00 0x400000>;
				dma-ranges = <0x10 0x00 0x43000000 0x10 0x00 0x10 0x00 0xc0 0x40000000 0x2000000 0x00 0x00 0x00 0x400000 0x00 0x00 0x2000000 0x10 0x00 0x10 0x00>;
				phandle = <0x31>;

				clocks@18000 {
					compatible = "raspberrypi,rp1-clocks";
					#clock-cells = <0x01>;
					reg = <0xc0 0x40018000 0x00 0x10038>;
					clocks = <0x32>;
					assigned-clocks = <0x33 0x00 0x33 0x01 0x33 0x03 0x33 0x09 0x33 0x04 0x33 0x0a 0x33 0x0c 0x33 0x06 0x33 0x0d 0x33 0x1f 0x33 0x20 0x33 0x1d>;
					assigned-clock-rates = <0x3b9aca00 0x5b8d8000 0xbebc200 0x7735940 0x3a98000 0xb71b000 0xbebc200 0x5f5e100 0x2faf080 0xf4240 0xbebc200 0x2faf080>;
					phandle = <0x33>;
				};

				serial@30000 {
					compatible = "arm,pl011-axi";
					reg = <0xc0 0x40030000 0x00 0x100>;
					interrupts = <0x19 0x04>;
					clocks = <0x33 0x0f 0x33 0x06>;
					clock-names = "uartclk", "apb_pclk";
					pinctrl-names = "default";
					arm,primecell-periphid = <0x541011>;
					uart-has-rtscts;
					cts-event-workaround;
					skip-init;
					status = "disabled";
					pinctrl-0 = <0x34>;
					phandle = <0x71>;
				};

				serial@34000 {
					compatible = "arm,pl011-axi";
					reg = <0xc0 0x40034000 0x00 0x100>;
					interrupts = <0x2a 0x04>;
					clocks = <0x33 0x0f 0x33 0x06>;
					clock-names = "uartclk", "apb_pclk";
					pinctrl-names = "default";
					arm,primecell-periphid = <0x541011>;
					uart-has-rtscts;
					cts-event-workaround;
					skip-init;
					status = "disabled";
					phandle = <0xba>;
				};

				serial@38000 {
					compatible = "arm,pl011-axi";
					reg = <0xc0 0x40038000 0x00 0x100>;
					interrupts = <0x2b 0x04>;
					clocks = <0x33 0x0f 0x33 0x06>;
					clock-names = "uartclk", "apb_pclk";
					pinctrl-names = "default";
					arm,primecell-periphid = <0x541011>;
					uart-has-rtscts;
					cts-event-workaround;
					skip-init;
					status = "disabled";
					phandle = <0xbb>;
				};

				serial@3c000 {
					compatible = "arm,pl011-axi";
					reg = <0xc0 0x4003c000 0x00 0x100>;
					interrupts = <0x2c 0x04>;
					clocks = <0x33 0x0f 0x33 0x06>;
					clock-names = "uartclk", "apb_pclk";
					pinctrl-names = "default";
					arm,primecell-periphid = <0x541011>;
					uart-has-rtscts;
					cts-event-workaround;
					skip-init;
					status = "disabled";
					phandle = <0xbc>;
				};

				serial@40000 {
					compatible = "arm,pl011-axi";
					reg = <0xc0 0x40040000 0x00 0x100>;
					interrupts = <0x2d 0x04>;
					clocks = <0x33 0x0f 0x33 0x06>;
					clock-names = "uartclk", "apb_pclk";
					pinctrl-names = "default";
					arm,primecell-periphid = <0x541011>;
					uart-has-rtscts;
					cts-event-workaround;
					skip-init;
					status = "disabled";
					phandle = <0xbd>;
				};

				serial@44000 {
					compatible = "arm,pl011-axi";
					reg = <0xc0 0x40044000 0x00 0x100>;
					interrupts = <0x2e 0x04>;
					clocks = <0x33 0x0f 0x33 0x06>;
					clock-names = "uartclk", "apb_pclk";
					pinctrl-names = "default";
					arm,primecell-periphid = <0x541011>;
					uart-has-rtscts;
					cts-event-workaround;
					skip-init;
					status = "disabled";
					phandle = <0xbe>;
				};

				spi@4c000 {
					reg = <0xc0 0x4004c000 0x00 0x130>;
					compatible = "snps,dw-apb-ssi";
					interrupts = <0x38 0x04>;
					clocks = <0x33 0x0c>;
					clock-names = "ssi_clk";
					#address-cells = <0x01>;
					#size-cells = <0x00>;
					num-cs = <0x02>;
					dmas = <0x35 0x37 0x35 0x36>;
					dma-names = "tx", "rx";
					status = "disabled";
					phandle = <0xbf>;
				};

				spi@50000 {
					reg = <0xc0 0x40050000 0x00 0x130>;
					compatible = "snps,dw-apb-ssi";
					interrupts = <0x13 0x04>;
					clocks = <0x33 0x0c>;
					clock-names = "ssi_clk";
					#address-cells = <0x01>;
					#size-cells = <0x00>;
					num-cs = <0x02>;
					dmas = <0x35 0x0d 0x35 0x0c>;
					dma-names = "tx", "rx";
					status = "disabled";
					pinctrl-names = "default";
					pinctrl-0 = <0x36 0x37>;
					cs-gpios = <0x38 0x08 0x01 0x38 0x07 0x01>;
					phandle = <0x6f>;

					spidev@0 {
						compatible = "spidev";
						reg = <0x00>;
						#address-cells = <0x01>;
						#size-cells = <0x00>;
						spi-max-frequency = <0x7735940>;
						phandle = <0xc0>;
					};

					spidev@1 {
						compatible = "spidev";
						reg = <0x01>;
						#address-cells = <0x01>;
						#size-cells = <0x00>;
						spi-max-frequency = <0x7735940>;
						phandle = <0xc1>;
					};
				};

				spi@54000 {
					reg = <0xc0 0x40054000 0x00 0x130>;
					compatible = "snps,dw-apb-ssi";
					interrupts = <0x14 0x04>;
					clocks = <0x33 0x0c>;
					clock-names = "ssi_clk";
					#address-cells = <0x01>;
					#size-cells = <0x00>;
					num-cs = <0x02>;
					dmas = <0x35 0x0f 0x35 0x0e>;
					dma-names = "tx", "rx";
					status = "disabled";
					phandle = <0xc2>;
				};

				spi@58000 {
					reg = <0xc0 0x40058000 0x00 0x130>;
					compatible = "snps,dw-apb-ssi";
					interrupts = <0x15 0x04>;
					clocks = <0x33 0x0c>;
					clock-names = "ssi_clk";
					#address-cells = <0x01>;
					#size-cells = <0x00>;
					num-cs = <0x02>;
					dmas = <0x35 0x11 0x35 0x10>;
					dma-names = "tx", "rx";
					status = "disabled";
					pinctrl-names = "default";
					pinctrl-0 = <0x39>;
					phandle = <0xc3>;
				};

				spi@5c000 {
					reg = <0xc0 0x4005c000 0x00 0x130>;
					compatible = "snps,dw-apb-ssi";
					interrupts = <0x16 0x04>;
					clocks = <0x33 0x0c>;
					clock-names = "ssi_clk";
					#address-cells = <0x01>;
					#size-cells = <0x00>;
					num-cs = <0x02>;
					dmas = <0x35 0x13 0x35 0x12>;
					dma-names = "tx", "rx";
					status = "disabled";
					pinctrl-names = "default";
					pinctrl-0 = <0x3a>;
					phandle = <0xc4>;
				};

				spi@60000 {
					reg = <0xc0 0x40060000 0x00 0x130>;
					compatible = "snps,dw-apb-ssi";
					interrupts = <0x17 0x04>;
					clocks = <0x33 0x0c>;
					clock-names = "ssi_clk";
					#address-cells = <0x00>;
					#size-cells = <0x00>;
					num-cs = <0x01>;
					spi-slave;
					dmas = <0x35 0x15 0x35 0x14>;
					dma-names = "tx", "rx";
					status = "disabled";
					pinctrl-names = "default";
					pinctrl-0 = <0x3b>;
					phandle = <0xc5>;

					slave {
						compatible = "spidev";
						spi-max-frequency = <0xf4240>;
					};
				};

				spi@64000 {
					reg = <0xc0 0x40064000 0x00 0x130>;
					compatible = "snps,dw-apb-ssi";
					interrupts = <0x18 0x04>;
					clocks = <0x33 0x0c>;
					clock-names = "ssi_clk";
					#address-cells = <0x01>;
					#size-cells = <0x00>;
					num-cs = <0x02>;
					dmas = <0x35 0x17 0x35 0x16>;
					dma-names = "tx", "rx";
					status = "disabled";
					pinctrl-names = "default";
					pinctrl-0 = <0x3c>;
					phandle = <0xc6>;
				};

				spi@68000 {
					reg = <0xc0 0x40068000 0x00 0x130>;
					compatible = "snps,dw-apb-ssi";
					interrupts = <0x36 0x04>;
					clocks = <0x33 0x0c>;
					clock-names = "ssi_clk";
					#address-cells = <0x01>;
					#size-cells = <0x00>;
					num-cs = <0x02>;
					dmas = <0x35 0x33 0x35 0x32>;
					dma-names = "tx", "rx";
					status = "disabled";
					phandle = <0xc7>;
				};

				spi@6c000 {
					reg = <0xc0 0x4006c000 0x00 0x130>;
					compatible = "snps,dw-apb-ssi";
					interrupts = <0x37 0x04>;
					clocks = <0x33 0x0c>;
					clock-names = "ssi_clk";
					#address-cells = <0x00>;
					#size-cells = <0x00>;
					num-cs = <0x01>;
					spi-slave;
					dmas = <0x35 0x35 0x35 0x34>;
					dma-names = "tx", "rx";
					status = "disabled";
					phandle = <0xc8>;

					slave {
						compatible = "spidev";
						spi-max-frequency = <0xf4240>;
					};
				};

				i2c@70000 {
					reg = <0xc0 0x40070000 0x00 0x1000>;
					compatible = "snps,designware-i2c";
					interrupts = <0x07 0x04>;
					clocks = <0x33 0x0c>;
					i2c-scl-rising-time-ns = <0x41>;
					i2c-scl-falling-time-ns = <0x64>;
					status = "disabled";
					pinctrl-0 = <0x3d>;
					pinctrl-names = "default";
					clock-frequency = <0x186a0>;
					phandle = <0x67>;
				};

				i2c@74000 {
					reg = <0xc0 0x40074000 0x00 0x1000>;
					compatible = "snps,designware-i2c";
					interrupts = <0x08 0x04>;
					clocks = <0x33 0x0c>;
					i2c-scl-rising-time-ns = <0x41>;
					i2c-scl-falling-time-ns = <0x64>;
					status = "disabled";
					pinctrl-names = "default";
					pinctrl-0 = <0x3e>;
					clock-frequency = <0x186a0>;
					phandle = <0x64>;
				};

				i2c@78000 {
					reg = <0xc0 0x40078000 0x00 0x1000>;
					compatible = "snps,designware-i2c";
					interrupts = <0x09 0x04>;
					clocks = <0x33 0x0c>;
					i2c-scl-rising-time-ns = <0x41>;
					i2c-scl-falling-time-ns = <0x64>;
					status = "disabled";
					pinctrl-names = "default";
					pinctrl-0 = <0x3f>;
					phandle = <0xc9>;
				};

				i2c@7c000 {
					reg = <0xc0 0x4007c000 0x00 0x1000>;
					compatible = "snps,designware-i2c";
					interrupts = <0x0a 0x04>;
					clocks = <0x33 0x0c>;
					i2c-scl-rising-time-ns = <0x41>;
					i2c-scl-falling-time-ns = <0x64>;
					status = "disabled";
					pinctrl-names = "default";
					pinctrl-0 = <0x40>;
					phandle = <0xca>;
				};

				i2c@80000 {
					reg = <0xc0 0x40080000 0x00 0x1000>;
					compatible = "snps,designware-i2c";
					interrupts = <0x0b 0x04>;
					clocks = <0x33 0x0c>;
					i2c-scl-rising-time-ns = <0x41>;
					i2c-scl-falling-time-ns = <0x64>;
					status = "disabled";
					pinctrl-0 = <0x41>;
					pinctrl-names = "default";
					clock-frequency = <0x186a0>;
					phandle = <0x65>;
				};

				i2c@84000 {
					reg = <0xc0 0x40084000 0x00 0x1000>;
					compatible = "snps,designware-i2c";
					interrupts = <0x0c 0x04>;
					clocks = <0x33 0x0c>;
					i2c-scl-rising-time-ns = <0x41>;
					i2c-scl-falling-time-ns = <0x64>;
					status = "disabled";
					phandle = <0xcb>;
				};

				i2c@88000 {
					reg = <0xc0 0x40088000 0x00 0x1000>;
					compatible = "snps,designware-i2c";
					interrupts = <0x0d 0x04>;
					clocks = <0x33 0x0c>;
					i2c-scl-rising-time-ns = <0x41>;
					i2c-scl-falling-time-ns = <0x64>;
					status = "disabled";
					pinctrl-0 = <0x42>;
					pinctrl-names = "default";
					clock-frequency = <0x186a0>;
					phandle = <0x66>;
				};

				pwm@98000 {
					compatible = "raspberrypi,rp1-pwm";
					reg = <0xc0 0x40098000 0x00 0x100>;
					#pwm-cells = <0x03>;
					clocks = <0x33 0x11>;
					assigned-clocks = <0x33 0x11>;
					assigned-clock-rates = <0x2faf080>;
					status = "disabled";
					phandle = <0xcc>;
				};

				pwm@9c000 {
					compatible = "raspberrypi,rp1-pwm";
					reg = <0xc0 0x4009c000 0x00 0x100>;
					#pwm-cells = <0x03>;
					clocks = <0x33 0x12>;
					assigned-clocks = <0x33 0x12>;
					assigned-clock-rates = <0x2faf080>;
					status = "disabled";
					pinctrl-0 = <0x43>;
					pinctrl-names = "default";
					phandle = <0x62>;
				};

				i2s@a0000 {
					reg = <0xc0 0x400a0000 0x00 0x1000>;
					compatible = "snps,designware-i2s";
					clocks = <0x33 0x15>;
					clock-names = "i2sclk";
					#sound-dai-cells = <0x00>;
					dmas = <0x35 0x20 0x35 0x1f>;
					dma-names = "tx", "rx";
					dma-maxburst = <0x04>;
					status = "disabled";
					pinctrl-names = "default";
					pinctrl-0 = <0x44>;
					phandle = <0xcd>;
				};

				i2s@a4000 {
					reg = <0xc0 0x400a4000 0x00 0x1000>;
					compatible = "snps,designware-i2s";
					clocks = <0x33 0x15>;
					clock-names = "i2sclk";
					#sound-dai-cells = <0x00>;
					dmas = <0x35 0x22 0x35 0x21>;
					dma-names = "tx", "rx";
					dma-maxburst = <0x04>;
					status = "disabled";
					pinctrl-names = "default";
					pinctrl-0 = <0x45>;
					phandle = <0xce>;
				};

				i2s@a8000 {
					reg = <0xc0 0x400a8000 0x00 0x1000>;
					compatible = "snps,designware-i2s";
					clocks = <0x33 0x15>;
					status = "disabled";
					phandle = <0xcf>;
				};

				sdio_clk0@b0004 {
					compatible = "raspberrypi,rp1-sdio-clk";
					reg = <0xc0 0x400b0004 0x00 0x1c>;
					clocks = <0x46 0x47>;
					clock-names = "src", "base";
					#clock-cells = <0x00>;
					status = "disabled";
					phandle = <0x4d>;
				};

				sdio_clk1@b4004 {
					compatible = "raspberrypi,rp1-sdio-clk";
					reg = <0xc0 0x400b4004 0x00 0x1c>;
					clocks = <0x46 0x47>;
					clock-names = "src", "base";
					#clock-cells = <0x00>;
					status = "disabled";
					phandle = <0x4e>;
				};

				adc@c8000 {
					compatible = "raspberrypi,rp1-adc";
					reg = <0xc0 0x400c8000 0x00 0x4000>;
					clocks = <0x33 0x1e>;
					clock-names = "adcclk";
					#clock-cells = <0x00>;
					vref-supply = <0x48>;
					status = "okay";
					phandle = <0xd0>;
				};

				gpio@d0000 {
					reg = <0xc0 0x400d0000 0x00 0xc000 0xc0 0x400e0000 0x00 0xc000 0xc0 0x400f0000 0x00 0xc000>;
					compatible = "raspberrypi,rp1-gpio";
					interrupts = <0x00 0x04 0x01 0x04 0x02 0x04>;
					gpio-controller;
					#gpio-cells = <0x02>;
					interrupt-controller;
					#interrupt-cells = <0x02>;
					gpio-ranges = <0x38 0x00 0x00 0x36>;
					status = "okay";
					gpio-line-names = "ID_SDA", "ID_SCL", "GPIO2", "GPIO3", "GPIO4", "GPIO5", "GPIO6", "GPIO7", "GPIO8", "GPIO9", "GPIO10", "GPIO11", "GPIO12", "GPIO13", "GPIO14", "GPIO15", "GPIO16", "GPIO17", "GPIO18", "GPIO19", "GPIO20", "GPIO21", "GPIO22", "GPIO23", "GPIO24", "GPIO25", "GPIO26", "GPIO27", "PCIE_RP1_WAKE", "FAN_TACH", "HOST_SDA", "HOST_SCL", "ETH_RST_N", "-", "CD0_IO0_MICCLK", "CD0_IO0_MICDAT0", "RP1_PCIE_CLKREQ_N", "-", "CD0_SDA", "CD0_SCL", "CD1_SDA", "CD1_SCL", "USB_VBUS_EN", "USB_OC_N", "RP1_STAT_LED", "FAN_PWM", "CD1_IO0_MICCLK", "2712_WAKE", "CD1_IO1_MICDAT1", "EN_MAX_USB_CUR", "-", "-", "-", "-";
					phandle = <0x38>;

					rp1_uart0_14_15 {
						phandle = <0x34>;

						pin_txd {
							function = "uart0";
							pins = "gpio14";
							bias-disable;
						};

						pin_rxd {
							function = "uart0";
							pins = "gpio15";
							bias-pull-up;
						};
					};

					rp1_uart0_ctsrts_16_17 {
						phandle = <0xd1>;

						pin_cts {
							function = "uart0";
							pins = "gpio16";
							bias-pull-up;
						};

						pin_rts {
							function = "uart0";
							pins = "gpio17";
							bias-disable;
						};
					};

					rp1_uart1_0_1 {
						phandle = <0xd2>;

						pin_txd {
							function = "uart1";
							pins = "gpio0";
							bias-disable;
						};

						pin_rxd {
							function = "uart1";
							pins = "gpio1";
							bias-pull-up;
						};
					};

					rp1_uart1_ctsrts_2_3 {
						phandle = <0xd3>;

						pin_cts {
							function = "uart1";
							pins = "gpio2";
							bias-pull-up;
						};

						pin_rts {
							function = "uart1";
							pins = "gpio3";
							bias-disable;
						};
					};

					rp1_uart2_4_5 {
						phandle = <0xd4>;

						pin_txd {
							function = "uart2";
							pins = "gpio4";
							bias-disable;
						};

						pin_rxd {
							function = "uart2";
							pins = "gpio5";
							bias-pull-up;
						};
					};

					rp1_uart2_ctsrts_6_7 {
						phandle = <0xd5>;

						pin_cts {
							function = "uart2";
							pins = "gpio6";
							bias-pull-up;
						};

						pin_rts {
							function = "uart2";
							pins = "gpio7";
							bias-disable;
						};
					};

					rp1_uart3_8_9 {
						phandle = <0xd6>;

						pin_txd {
							function = "uart3";
							pins = "gpio8";
							bias-disable;
						};

						pin_rxd {
							function = "uart3";
							pins = "gpio9";
							bias-pull-up;
						};
					};

					rp1_uart3_ctsrts_10_11 {
						phandle = <0xd7>;

						pin_cts {
							function = "uart3";
							pins = "gpio10";
							bias-pull-up;
						};

						pin_rts {
							function = "uart3";
							pins = "gpio11";
							bias-disable;
						};
					};

					rp1_uart4_12_13 {
						phandle = <0xd8>;

						pin_txd {
							function = "uart4";
							pins = "gpio12";
							bias-disable;
						};

						pin_rxd {
							function = "uart4";
							pins = "gpio13";
							bias-pull-up;
						};
					};

					rp1_uart4_ctsrts_14_15 {
						phandle = <0xd9>;

						pin_cts {
							function = "uart4";
							pins = "gpio14";
							bias-pull-up;
						};

						pin_rts {
							function = "uart4";
							pins = "gpio15";
							bias-disable;
						};
					};

					rp1_sdio0_22_27 {
						phandle = <0xda>;

						pin_clk {
							function = "sd0";
							pins = "gpio22";
							bias-disable;
							drive-strength = <0x0c>;
							slew-rate = <0x01>;
						};

						pin_cmd {
							function = "sd0";
							pins = "gpio23";
							bias-pull-up;
							drive-strength = <0x0c>;
							slew-rate = <0x01>;
						};

						pins_dat {
							function = "sd0";
							pins = "gpio24", "gpio25", "gpio26", "gpio27";
							bias-pull-up;
							drive-strength = <0x0c>;
							slew-rate = <0x01>;
						};
					};

					rp1_sdio1_28_33 {
						phandle = <0xdb>;

						pin_clk {
							function = "sd1";
							pins = "gpio28";
							bias-disable;
							drive-strength = <0x0c>;
							slew-rate = <0x01>;
						};

						pin_cmd {
							function = "sd1";
							pins = "gpio29";
							bias-pull-up;
							drive-strength = <0x0c>;
							slew-rate = <0x01>;
						};

						pins_dat {
							function = "sd1";
							pins = "gpio30", "gpio31", "gpio32", "gpio33";
							bias-pull-up;
							drive-strength = <0x0c>;
							slew-rate = <0x01>;
						};
					};

					rp1_i2s0_18_21 {
						function = "i2s0";
						pins = "gpio18", "gpio19", "gpio20", "gpio21";
						bias-disable;
						phandle = <0x44>;
					};

					rp1_i2s1_18_21 {
						function = "i2s1";
						pins = "gpio18", "gpio19", "gpio20", "gpio21";
						bias-disable;
						phandle = <0x45>;
					};

					rp1_i2c4_34_35 {
						function = "i2c4";
						pins = "gpio34", "gpio35";
						drive-strength = <0x0c>;
						bias-pull-up;
						phandle = <0xdc>;
					};

					rp1_i2c6_38_39 {
						function = "i2c6";
						pins = "gpio38", "gpio39";
						drive-strength = <0x0c>;
						bias-pull-up;
						phandle = <0x42>;
					};

					rp1_i2c4_40_41 {
						function = "i2c4";
						pins = "gpio40", "gpio41";
						drive-strength = <0x0c>;
						bias-pull-up;
						phandle = <0x41>;
					};

					rp1_i2c5_44_45 {
						function = "i2c5";
						pins = "gpio44", "gpio45";
						drive-strength = <0x0c>;
						bias-pull-up;
						phandle = <0xdd>;
					};

					rp1_i2c0_0_1 {
						function = "i2c0";
						pins = "gpio0", "gpio1";
						drive-strength = <0x0c>;
						bias-pull-up;
						phandle = <0x3d>;
					};

					rp1_i2c0_8_9 {
						function = "i2c0";
						pins = "gpio8", "gpio9";
						drive-strength = <0x0c>;
						bias-pull-up;
						phandle = <0xde>;
					};

					rp1_i2c1_2_3 {
						function = "i2c1";
						pins = "gpio2", "gpio3";
						drive-strength = <0x0c>;
						bias-pull-up;
						phandle = <0x3e>;
					};

					rp1_i2c1_10_11 {
						function = "i2c1";
						pins = "gpio10", "gpio11";
						drive-strength = <0x0c>;
						bias-pull-up;
						phandle = <0xdf>;
					};

					rp1_i2c2_4_5 {
						function = "i2c2";
						pins = "gpio4", "gpio5";
						drive-strength = <0x0c>;
						bias-pull-up;
						phandle = <0x3f>;
					};

					rp1_i2c2_12_13 {
						function = "i2c2";
						pins = "gpio12", "gpio13";
						drive-strength = <0x0c>;
						bias-pull-up;
						phandle = <0xe0>;
					};

					rp1_i2c3_6_7 {
						function = "i2c3";
						pins = "gpio6", "gpio7";
						drive-strength = <0x0c>;
						bias-pull-up;
						phandle = <0x40>;
					};

					rp1_i2c3_14_15 {
						function = "i2c3";
						pins = "gpio14", "gpio15";
						drive-strength = <0x0c>;
						bias-pull-up;
						phandle = <0xe1>;
					};

					rp1_i2c3_22_23 {
						function = "i2c3";
						pins = "gpio22", "gpio23";
						drive-strength = <0x0c>;
						bias-pull-up;
						phandle = <0xe2>;
					};

					rp1_dpi_16bit_gpio2 {
						function = "dpi";
						pins = "gpio2", "gpio3", "gpio4", "gpio5", "gpio6", "gpio7", "gpio8", "gpio9", "gpio10", "gpio11", "gpio12", "gpio13", "gpio14", "gpio15", "gpio16", "gpio17", "gpio18", "gpio19";
						bias-disable;
						phandle = <0xe3>;
					};

					rp1_dpi_16bit_cpadhi_gpio2 {
						function = "dpi";
						pins = "gpio2", "gpio3", "gpio4", "gpio5", "gpio6", "gpio7", "gpio8", "gpio12", "gpio13", "gpio14", "gpio15", "gpio16", "gpio17", "gpio20", "gpio21", "gpio22", "gpio23", "gpio24";
						bias-disable;
						phandle = <0xe4>;
					};

					rp1_dpi_16bit_pad666_gpio2 {
						function = "dpi";
						pins = "gpio2", "gpio3", "gpio5", "gpio6", "gpio7", "gpio8", "gpio9", "gpio12", "gpio13", "gpio14", "gpio15", "gpio16", "gpio17", "gpio21", "gpio22", "gpio23", "gpio24", "gpio25";
						bias-disable;
						phandle = <0xe5>;
					};

					rp1_dpi_18bit_gpio2 {
						function = "dpi";
						pins = "gpio2", "gpio3", "gpio4", "gpio5", "gpio6", "gpio7", "gpio8", "gpio9", "gpio10", "gpio11", "gpio12", "gpio13", "gpio14", "gpio15", "gpio16", "gpio17", "gpio18", "gpio19", "gpio20", "gpio21";
						bias-disable;
						phandle = <0xe6>;
					};

					rp1_dpi_18bit_cpadhi_gpio2 {
						function = "dpi";
						pins = "gpio2", "gpio3", "gpio4", "gpio5", "gpio6", "gpio7", "gpio8", "gpio9", "gpio12", "gpio13", "gpio14", "gpio15", "gpio16", "gpio17", "gpio20", "gpio21", "gpio22", "gpio23", "gpio24", "gpio25";
						bias-disable;
						phandle = <0xe7>;
					};

					rp1_dpi_24bit_gpio2 {
						function = "dpi";
						pins = "gpio2", "gpio3", "gpio4", "gpio5", "gpio6", "gpio7", "gpio8", "gpio9", "gpio10", "gpio11", "gpio12", "gpio13", "gpio14", "gpio15", "gpio16", "gpio17", "gpio18", "gpio19", "gpio20", "gpio21", "gpio22", "gpio23", "gpio24", "gpio25", "gpio26", "gpio27";
						bias-disable;
						phandle = <0xe8>;
					};

					rp1_dpi_hvsync {
						function = "dpi";
						pins = "gpio2", "gpio3";
						bias-disable;
						phandle = <0xe9>;
					};

					rp1_dpi_16bit_gpio0 {
						function = "dpi";
						pins = "gpio0", "gpio1", "gpio2", "gpio3", "gpio4", "gpio5", "gpio6", "gpio7", "gpio8", "gpio9", "gpio10", "gpio11", "gpio12", "gpio13", "gpio14", "gpio15", "gpio16", "gpio17", "gpio18", "gpio19";
						bias-disable;
						phandle = <0xea>;
					};

					rp1_dpi_16bit_cpadhi_gpio0 {
						function = "dpi";
						pins = "gpio0", "gpio1", "gpio2", "gpio3", "gpio4", "gpio5", "gpio6", "gpio7", "gpio8", "gpio12", "gpio13", "gpio14", "gpio15", "gpio16", "gpio17", "gpio20", "gpio21", "gpio22", "gpio23", "gpio24";
						bias-disable;
						phandle = <0xeb>;
					};

					rp1_dpi_16bit_pad666_gpio0 {
						function = "dpi";
						pins = "gpio0", "gpio1", "gpio2", "gpio3", "gpio5", "gpio6", "gpio7", "gpio8", "gpio9", "gpio12", "gpio13", "gpio14", "gpio15", "gpio16", "gpio17", "gpio21", "gpio22", "gpio23", "gpio24", "gpio25";
						bias-disable;
						phandle = <0xec>;
					};

					rp1_dpi_18bit_gpio0 {
						function = "dpi";
						pins = "gpio0", "gpio1", "gpio2", "gpio3", "gpio4", "gpio5", "gpio6", "gpio7", "gpio8", "gpio9", "gpio10", "gpio11", "gpio12", "gpio13", "gpio14", "gpio15", "gpio16", "gpio17", "gpio18", "gpio19", "gpio20", "gpio21";
						bias-disable;
						phandle = <0xed>;
					};

					rp1_dpi_18bit_cpadhi_gpio0 {
						function = "dpi";
						pins = "gpio0", "gpio1", "gpio2", "gpio3", "gpio4", "gpio5", "gpio6", "gpio7", "gpio8", "gpio9", "gpio12", "gpio13", "gpio14", "gpio15", "gpio16", "gpio17", "gpio20", "gpio21", "gpio22", "gpio23", "gpio24", "gpio25";
						bias-disable;
						phandle = <0xee>;
					};

					rp1_dpi_24bit_gpio0 {
						function = "dpi";
						pins = "gpio0", "gpio1", "gpio2", "gpio3", "gpio4", "gpio5", "gpio6", "gpio7", "gpio8", "gpio9", "gpio10", "gpio11", "gpio12", "gpio13", "gpio14", "gpio15", "gpio16", "gpio17", "gpio18", "gpio19", "gpio20", "gpio21", "gpio22", "gpio23", "gpio24", "gpio25", "gpio26", "gpio27";
						bias-disable;
						phandle = <0xef>;
					};

					rp1_gpclksrc0_gpio4 {
						function = "gpclk0";
						pins = "gpio4";
						bias-disable;
						phandle = <0xf0>;
					};

					rp1_gpclksrc0_gpio20 {
						function = "gpclk0";
						pins = "gpio20";
						bias-disable;
						phandle = <0xf1>;
					};

					rp1_gpclksrc1_gpio5 {
						function = "gpclk1";
						pins = "gpio5";
						bias-disable;
						phandle = <0xf2>;
					};

					rp1_gpclksrc1_gpio18 {
						function = "gpclk1";
						pins = "gpio18";
						bias-disable;
						phandle = <0xf3>;
					};

					rp1_gpclksrc1_gpio21 {
						function = "gpclk1";
						pins = "gpio21";
						bias-disable;
						phandle = <0xf4>;
					};

					rp1_pwm1_gpio45 {
						function = "pwm1";
						pins = "gpio45";
						bias-pull-down;
						phandle = <0x43>;
					};

					rp1_spi0_gpio9 {
						function = "spi0";
						pins = "gpio9", "gpio10", "gpio11";
						bias-disable;
						drive-strength = <0x0c>;
						slew-rate = <0x01>;
						phandle = <0x36>;
					};

					rp1_spi0_cs_gpio7 {
						function = "spi0";
						pins = "gpio7", "gpio8";
						bias-pull-up;
						phandle = <0x37>;
					};

					rp1_spi1_gpio19 {
						function = "spi1";
						pins = "gpio19", "gpio20", "gpio21";
						bias-disable;
						drive-strength = <0x0c>;
						slew-rate = <0x01>;
						phandle = <0xf5>;
					};

					rp1_spi2_gpio1 {
						function = "spi2";
						pins = "gpio1", "gpio2", "gpio3";
						bias-disable;
						drive-strength = <0x0c>;
						slew-rate = <0x01>;
						phandle = <0x39>;
					};

					rp1_spi3_gpio5 {
						function = "spi3";
						pins = "gpio5", "gpio6", "gpio7";
						bias-disable;
						drive-strength = <0x0c>;
						slew-rate = <0x01>;
						phandle = <0x3a>;
					};

					rp1_spi4_gpio9 {
						function = "spi4";
						pins = "gpio9", "gpio10", "gpio11";
						bias-disable;
						drive-strength = <0x0c>;
						slew-rate = <0x01>;
						phandle = <0x3b>;
					};

					rp1_spi5_gpio13 {
						function = "spi5";
						pins = "gpio13", "gpio14", "gpio15";
						bias-disable;
						drive-strength = <0x0c>;
						slew-rate = <0x01>;
						phandle = <0x3c>;
					};

					rp1_spi8_gpio49 {
						function = "spi8";
						pins = "gpio49", "gpio50", "gpio51";
						bias-disable;
						drive-strength = <0x0c>;
						slew-rate = <0x01>;
						phandle = <0xf6>;
					};

					rp1_spi8_cs_gpio52 {
						function = "spi0";
						pins = "gpio52", "gpio53";
						bias-pull-up;
						phandle = <0xf7>;
					};

					usb_vbus_pins {
						function = "vbus1";
						pins = "gpio42", "gpio43";
						phandle = <0x4f>;
					};
				};

				ethernet@100000 {
					reg = <0xc0 0x40100000 0x00 0x4000>;
					compatible = "cdns,macb";
					#address-cells = <0x01>;
					#size-cells = <0x00>;
					interrupts = <0x06 0x04>;
					clocks = <0x49 0x4a 0x33 0x1d>;
					clock-names = "pclk", "hclk", "tsu_clk";
					phy-mode = "rgmii-id";
					cdns,aw2w-max-pipe = [08];
					cdns,ar2r-max-pipe = [08];
					cdns,use-aw2b-fill;
					local-mac-address = [00 00 00 00 00 00];
					status = "okay";
					phy-handle = <0x4b>;
					phy-reset-gpios = <0x38 0x20 0x01>;
					phy-reset-duration = <0x05>;
					phandle = <0xf8>;

					ethernet-phy@1 {
						reg = <0x01>;
						brcm,powerdown-enable;
						phandle = <0x4b>;
					};
				};

				csi@110000 {
					compatible = "raspberrypi,rp1-cfe";
					reg = <0xc0 0x40110000 0x00 0x100 0xc0 0x40114000 0x00 0x100 0xc0 0x40120000 0x00 0x100 0xc0 0x40124000 0x00 0x1000>;
					interrupts = <0x2f 0x04>;
					clocks = <0x33 0x16>;
					assigned-clocks = <0x33 0x16>;
					assigned-clock-rates = <0x17d7840>;
					#address-cells = <0x01>;
					#size-cells = <0x00>;
					status = "disabled";
					iommus = <0x4c>;
					phandle = <0xf9>;
				};

				csi@128000 {
					compatible = "raspberrypi,rp1-cfe";
					reg = <0xc0 0x40128000 0x00 0x100 0xc0 0x4012c000 0x00 0x100 0xc0 0x40138000 0x00 0x100 0xc0 0x4013c000 0x00 0x1000>;
					interrupts = <0x30 0x04>;
					clocks = <0x33 0x17>;
					assigned-clocks = <0x33 0x17>;
					assigned-clock-rates = <0x17d7840>;
					#address-cells = <0x01>;
					#size-cells = <0x00>;
					status = "disabled";
					iommus = <0x4c>;
					phandle = <0xfa>;
				};

				mmc@180000 {
					reg = <0xc0 0x40180000 0x00 0x100>;
					compatible = "raspberrypi,rp1-dwcmshc";
					interrupts = <0x11 0x04>;
					clocks = <0x33 0x0c 0x47 0x33 0x1f 0x4d>;
					clock-names = "bus", "core", "timeout", "sdio";
					no-1-8-v;
					bus-width = <0x04>;
					vmmc-supply = <0x48>;
					broken-cd;
					status = "disabled";
					phandle = <0xfb>;
				};

				mmc@184000 {
					reg = <0xc0 0x40184000 0x00 0x100>;
					compatible = "raspberrypi,rp1-dwcmshc";
					interrupts = <0x12 0x04>;
					clocks = <0x33 0x0c 0x47 0x33 0x1f 0x4e>;
					clock-names = "bus", "core", "timeout", "sdio";
					bus-width = <0x04>;
					vmmc-supply = <0x48>;
					sdhci-caps-mask = <0x03 0x00>;
					broken-cd;
					status = "disabled";
					phandle = <0xfc>;
				};

				dma@188000 {
					reg = <0xc0 0x40188000 0x00 0x1000>;
					compatible = "snps,axi-dma-1.01a";
					interrupts = <0x28 0x04>;
					clocks = <0x47 0x33 0x0c>;
					clock-names = "core-clk", "cfgr-clk";
					#dma-cells = <0x01>;
					dma-channels = <0x08>;
					snps,dma-masters = <0x01>;
					snps,dma-targets = <0x40>;
					snps,data-width = <0x04>;
					snps,block-size = <0x40000 0x40000 0x40000 0x40000 0x40000 0x40000 0x40000 0x40000>;
					snps,priority = <0x00 0x01 0x02 0x03 0x04 0x05 0x06 0x07>;
					snps,axi-max-burst-len = <0x04>;
					status = "okay";
					phandle = <0x35>;
				};

				usb@200000 {
					reg = <0xc0 0x40200000 0x00 0x100000>;
					compatible = "snps,dwc3";
					dr_mode = "host";
					usb3-lpm-capable;
					snps,axi-pipe-limit = [08];
					snps,dis_rxdet_inp3_quirk;
					snps,parkmode-disable-ss-quirk;
					snps,parkmode-disable-hs-quirk;
					snps,parkmode-disable-fsls-quirk;
					snps,tx-max-burst = [08];
					snps,tx-thr-num-pkt = [02];
					interrupts = <0x1f 0x01>;
					status = "okay";
					pinctrl-0 = <0x4f>;
					pinctrl-names = "default";
					phandle = <0xfd>;
				};

				usb@300000 {
					reg = <0xc0 0x40300000 0x00 0x100000>;
					compatible = "snps,dwc3";
					dr_mode = "host";
					usb3-lpm-capable;
					snps,axi-pipe-limit = [08];
					snps,dis_rxdet_inp3_quirk;
					snps,parkmode-disable-ss-quirk;
					snps,parkmode-disable-hs-quirk;
					snps,parkmode-disable-fsls-quirk;
					snps,tx-max-burst = [08];
					snps,tx-thr-num-pkt = [02];
					interrupts = <0x24 0x01>;
					status = "okay";
					phandle = <0xfe>;
				};

				dsi@110000 {
					compatible = "raspberrypi,rp1dsi";
					status = "disabled";
					reg = <0xc0 0x40118000 0x00 0x1000 0xc0 0x4011c000 0x00 0x1000 0xc0 0x40120000 0x00 0x1000>;
					interrupts = <0x2f 0x04>;
					clocks = <0x33 0x16 0x33 0x29 0x33 0x2d 0x32 0x33 0x03>;
					clock-names = "cfgclk", "dpiclk", "byteclk", "refclk", "pllsys";
					assigned-clocks = <0x33 0x16>;
					assigned-clock-rates = <0x17d7840>;
					iommus = <0x4c>;
					phandle = <0xff>;
				};

				dsi@128000 {
					compatible = "raspberrypi,rp1dsi";
					status = "disabled";
					reg = <0xc0 0x40130000 0x00 0x1000 0xc0 0x40134000 0x00 0x1000 0xc0 0x40138000 0x00 0x1000>;
					interrupts = <0x30 0x04>;
					clocks = <0x33 0x17 0x33 0x2a 0x33 0x2e 0x32 0x33 0x03>;
					clock-names = "cfgclk", "dpiclk", "byteclk", "refclk", "pllsys";
					assigned-clocks = <0x33 0x17>;
					assigned-clock-rates = <0x17d7840>;
					iommus = <0x4c>;
					phandle = <0x100>;
				};

				vec@144000 {
					compatible = "raspberrypi,rp1vec";
					status = "disabled";
					reg = <0xc0 0x40144000 0x00 0x1000 0xc0 0x40140000 0x00 0x1000>;
					interrupts = <0x31 0x04>;
					clocks = <0x33 0x27>;
					assigned-clocks = <0x33 0x02 0x33 0x0b 0x33 0x27>;
					assigned-clock-rates = <0x46cf7100 0x66ff300 0x66ff300>;
					assigned-clock-parents = <0x00 0x33 0x02 0x33 0x0b>;
					iommus = <0x4c>;
					phandle = <0x101>;
				};

				dpi@148000 {
					compatible = "raspberrypi,rp1dpi";
					status = "disabled";
					reg = <0xc0 0x40148000 0x00 0x1000 0xc0 0x40140000 0x00 0x1000>;
					interrupts = <0x31 0x04>;
					clocks = <0x33 0x28 0x33 0x05 0x33 0x02>;
					clock-names = "dpiclk", "plldiv", "pllcore";
					assigned-clocks = <0x33 0x28>;
					assigned-clock-parents = <0x33 0x05>;
					iommus = <0x4c>;
					phandle = <0x102>;
				};

				gpiomem@d0000 {
					compatible = "raspberrypi,gpiomem";
					reg = <0xc0 0x400d0000 0x00 0x30000>;
					chardev-name = "gpiomem0";
				};
			};
		};

		msi-controller@130000 {
			compatible = "brcm,bcm2712-mip-intc";
			reg = <0x10 0x130000 0x00 0xc0>;
			msi-controller;
			interrupt-controller;
			#interrupt-cells = <0x02>;
			brcm,msi-base-spi = <0x80>;
			brcm,msi-num-spis = <0x40>;
			brcm,msi-offset = <0x00>;
			brcm,msi-pci-addr = <0xff 0xfffff000>;
			phandle = <0x30>;
		};

		msi-controller@131000 {
			compatible = "brcm,bcm2712-mip-intc";
			reg = <0x10 0x131000 0x00 0xc0>;
			msi-controller;
			interrupt-controller;
			#interrupt-cells = <0x02>;
			brcm,msi-base-spi = <0xf7>;
			brcm,msi-num-spis = <0x08>;
			brcm,msi-offset = <0x08>;
			brcm,msi-pci-addr = <0xff 0xffffe000>;
			phandle = <0x2f>;
		};

		syscon@400018 {
			compatible = "brcm,syscon-piarbctl", "syscon", "simple-mfd";
			reg = <0x10 0x400018 0x00 0x18>;
			phandle = <0x103>;
		};

		usb@480000 {
			compatible = "brcm,bcm2835-usb";
			reg = <0x10 0x480000 0x00 0x10000>;
			interrupts = <0x00 0x49 0x04>;
			#address-cells = <0x01>;
			#size-cells = <0x00>;
			clocks = <0x50>;
			clock-names = "otg";
			phys = <0x51>;
			phy-names = "usb2-phy";
			status = "disabled";
			power-domains = <0x52 0x06>;
			phandle = <0x104>;
		};

		codec@800000 {
			compatible = "raspberrypi,rpivid-vid-decoder";
			reg = <0x10 0x800000 0x00 0x10000 0x10 0x840000 0x00 0x1000>;
			reg-names = "hevc", "intc";
			interrupts = <0x00 0x62 0x04>;
			clocks = <0x0a 0x0b>;
			clock-names = "hevc";
			iommus = <0x53>;
			status = "okay";
			phandle = <0x105>;
		};

		mmc@fff000 {
			compatible = "brcm,bcm2712-sdhci";
			reg = <0x10 0xfff000 0x00 0x260 0x10 0xfff400 0x00 0x200 0x10 0x15040b0 0x00 0x04 0x10 0x15200f0 0x00 0x24>;
			reg-names = "host", "cfg", "busisol", "lcpll";
			interrupts = <0x00 0x111 0x04>;
			clocks = <0x54>;
			sdhci-caps-mask = <0xc000 0x00>;
			sdhci-caps = <0x00 0x00>;
			mmc-ddr-3_3v;
			pinctrl-0 = <0x55 0x56>;
			pinctrl-names = "default";
			vqmmc-supply = <0x57>;
			vmmc-supply = <0x58>;
			bus-width = <0x04>;
			sd-uhs-sdr50;
			sd-uhs-ddr50;
			sd-uhs-sdr104;
			cd-gpios = <0x59 0x05 0x01>;
			status = "okay";
			phandle = <0x75>;
		};

		mmc@1100000 {
			compatible = "brcm,bcm2712-sdhci";
			reg = <0x10 0x1100000 0x00 0x260 0x10 0x1100400 0x00 0x200>;
			reg-names = "host", "cfg";
			interrupts = <0x00 0x112 0x04>;
			clocks = <0x54>;
			sdhci-caps-mask = <0xc000 0x00>;
			sdhci-caps = <0x00 0x00>;
			supports-cqe;
			mmc-ddr-3_3v;
			status = "okay";
			pinctrl-0 = <0x5a>;
			pinctrl-names = "default";
			bus-width = <0x04>;
			vmmc-supply = <0x5b>;
			sd-uhs-ddr50;
			non-removable;
			#address-cells = <0x01>;
			#size-cells = <0x00>;
			phandle = <0x106>;

			wifi@1 {
				reg = <0x01>;
				compatible = "brcm,bcm4329-fmac";
				local-mac-address = [00 00 00 00 00 00];
				phandle = <0x72>;
			};
		};

		reset-controller@1504318 {
			compatible = "brcm,brcmstb-reset";
			reg = <0x10 0x1504318 0x00 0x30>;
			#reset-cells = <0x01>;
			phandle = <0x2c>;
		};

		v3d@2000000 {
			compatible = "brcm,2712-v3d";
			reg = <0x10 0x2000000 0x00 0x4000 0x10 0x2008000 0x00 0x6000>;
			reg-names = "hub", "core0";
			power-domains = <0x5c 0x01>;
			resets = <0x5c 0x00>;
			clocks = <0x0a 0x05>;
			clocks-names = "v3d";
			interrupts = <0x00 0xfa 0x04 0x00 0xf9 0x04>;
			status = "disabled";
			phandle = <0x107>;
		};

		interrupt-controller@7fff9000 {
			interrupt-controller;
			#interrupt-cells = <0x03>;
			compatible = "arm,gic-400";
			reg = <0x10 0x7fff9000 0x00 0x1000 0x10 0x7fffa000 0x00 0x2000 0x10 0x7fffc000 0x00 0x2000 0x10 0x7fffe000 0x00 0x2000>;
			interrupts = <0x01 0x09 0xf04>;
			phandle = <0x01>;
		};

		pisp_be@880000 {
			compatible = "raspberrypi,pispbe";
			reg = <0x10 0x880000 0x00 0x4000>;
			interrupts = <0x00 0x48 0x04>;
			clocks = <0x0a 0x07>;
			clocks-names = "isp_be";
			status = "okay";
			iommus = <0x53>;
			phandle = <0x108>;
		};
	};

	clocks {
		compatible = "simple-bus";
		#address-cells = <0x01>;
		#size-cells = <0x00>;
		phandle = <0x109>;

		clk-osc {
			compatible = "fixed-clock";
			#clock-cells = <0x00>;
			clock-output-names = "osc";
			clock-frequency = <0x337f980>;
			phandle = <0x15>;
		};

		clk-usb {
			compatible = "fixed-clock";
			#clock-cells = <0x00>;
			clock-output-names = "otg";
			clock-frequency = <0x1c9c3800>;
			phandle = <0x50>;
		};

		clk_vpu {
			#clock-cells = <0x00>;
			compatible = "fixed-clock";
			clock-frequency = <0x2cb41780>;
			clock-output-names = "vpu-clock";
			phandle = <0x0f>;
		};

		clk_uart {
			#clock-cells = <0x00>;
			compatible = "fixed-clock";
			clock-frequency = <0x8ca000>;
			clock-output-names = "uart-clock";
			phandle = <0x0e>;
		};

		clk_emmc2 {
			#clock-cells = <0x00>;
			compatible = "fixed-clock";
			clock-frequency = <0xbebc200>;
			clock-output-names = "emmc2-clock";
			phandle = <0x54>;
		};

		clk_xosc {
			compatible = "fixed-clock";
			#clock-cells = <0x00>;
			clock-output-names = "xosc";
			clock-frequency = <0x2faf080>;
			phandle = <0x32>;
		};

		macb_pclk {
			compatible = "fixed-clock";
			#clock-cells = <0x00>;
			clock-output-names = "pclk";
			clock-frequency = <0xbebc200>;
			phandle = <0x49>;
		};

		macb_hclk {
			compatible = "fixed-clock";
			#clock-cells = <0x00>;
			clock-output-names = "hclk";
			clock-frequency = <0xbebc200>;
			phandle = <0x4a>;
		};

		sdio_src {
			compatible = "fixed-clock";
			#clock-cells = <0x00>;
			clock-output-names = "src";
			clock-frequency = <0x3b9aca00>;
			phandle = <0x46>;
		};

		sdhci_core {
			compatible = "fixed-clock";
			#clock-cells = <0x00>;
			clock-output-names = "core";
			clock-frequency = <0x2faf080>;
			phandle = <0x47>;
		};

		clksrc_gp0 {
			status = "disabled";
			compatible = "fixed-factor-clock";
			#clock-cells = <0x00>;
			clock-div = <0x01>;
			clock-mult = <0x01>;
			clocks = <0x33 0x21>;
			clock-output-names = "clksrc_gp0";
			phandle = <0x10a>;
		};

		clksrc_gp1 {
			status = "disabled";
			compatible = "fixed-factor-clock";
			#clock-cells = <0x00>;
			clock-div = <0x01>;
			clock-mult = <0x01>;
			clocks = <0x33 0x22>;
			clock-output-names = "clksrc_gp1";
			phandle = <0x10b>;
		};

		clksrc_gp2 {
			status = "disabled";
			compatible = "fixed-factor-clock";
			clock-div = <0x01>;
			clock-mult = <0x01>;
			#clock-cells = <0x00>;
			clocks = <0x33 0x23>;
			clock-output-names = "clksrc_gp2";
			phandle = <0x10c>;
		};

		clksrc_gp3 {
			status = "disabled";
			compatible = "fixed-factor-clock";
			clock-div = <0x01>;
			clock-mult = <0x01>;
			#clock-cells = <0x00>;
			clocks = <0x33 0x24>;
			clock-output-names = "clksrc_gp3";
			phandle = <0x10d>;
		};

		clksrc_gp4 {
			status = "disabled";
			compatible = "fixed-factor-clock";
			#clock-cells = <0x00>;
			clock-div = <0x01>;
			clock-mult = <0x01>;
			clocks = <0x33 0x25>;
			clock-output-names = "clksrc_gp4";
			phandle = <0x10e>;
		};

		clksrc_gp5 {
			status = "disabled";
			compatible = "fixed-factor-clock";
			#clock-cells = <0x00>;
			clock-div = <0x01>;
			clock-mult = <0x01>;
			clocks = <0x33 0x26>;
			clock-output-names = "clksrc_gp5";
			phandle = <0x10f>;
		};
	};

	phy {
		compatible = "usb-nop-xceiv";
		#phy-cells = <0x00>;
		phandle = <0x51>;
	};

	memory@0 {
		device_type = "memory";
		reg = <0x00 0x00 0x28000000>;
	};

	leds {
		compatible = "gpio-leds";
		phandle = <0x110>;

		led-pwr {
			label = "PWR";
			gpios = <0x38 0x2c 0x01>;
			default-state = "off";
			linux,default-trigger = "none";
			phandle = <0x6c>;
		};

		led-act {
			label = "ACT";
			gpios = <0x59 0x09 0x01>;
			default-state = "off";
			linux,default-trigger = "mmc0";
			phandle = <0x5e>;
		};
	};

	sd_io_1v8_reg {
		compatible = "regulator-gpio";
		regulator-name = "vdd-sd-io";
		regulator-min-microvolt = <0x1b7740>;
		regulator-max-microvolt = <0x325aa0>;
		regulator-boot-on;
		regulator-always-on;
		regulator-settling-time-us = <0x1388>;
		gpios = <0x59 0x03 0x00>;
		states = <0x1b7740 0x01 0x325aa0 0x00>;
		status = "okay";
		phandle = <0x57>;
	};

	sd_vcc_reg {
		compatible = "regulator-fixed";
		regulator-name = "vcc-sd";
		regulator-min-microvolt = <0x325aa0>;
		regulator-max-microvolt = <0x325aa0>;
		regulator-boot-on;
		enable-active-high;
		gpios = <0x59 0x04 0x00>;
		status = "okay";
		phandle = <0x58>;
	};

	wl_on_reg {
		compatible = "regulator-fixed";
		regulator-name = "wl-on-regulator";
		regulator-min-microvolt = <0x325aa0>;
		regulator-max-microvolt = <0x325aa0>;
		pinctrl-0 = <0x5d>;
		pinctrl-names = "default";
		gpio = <0x11 0x1c 0x00>;
		startup-delay-us = <0x249f0>;
		enable-active-high;
		phandle = <0x5b>;
	};

	cam1_clk {
		compatible = "fixed-clock";
		#clock-cells = <0x00>;
		status = "disabled";
		phandle = <0x111>;
	};

	cam0_clk {
		compatible = "fixed-clock";
		#clock-cells = <0x00>;
		status = "disabled";
		phandle = <0x112>;
	};

	cam0_reg {
		compatible = "regulator-fixed";
		regulator-name = "cam0_reg";
		enable-active-high;
		status = "okay";
		gpio = <0x38 0x22 0x00>;
		phandle = <0x73>;
	};

	cam1_reg {
		compatible = "regulator-fixed";
		regulator-name = "cam1_reg";
		enable-active-high;
		status = "okay";
		gpio = <0x38 0x2e 0x00>;
		phandle = <0x74>;
	};

	cam_dummy_reg {
		compatible = "regulator-fixed";
		regulator-name = "cam-dummy-reg";
		status = "okay";
		phandle = <0x113>;
	};

	dummy {
		phandle = <0x114>;
	};

	i2c0if {
		phandle = <0x115>;
	};

	i2c0mux {
		phandle = <0x116>;
	};

	rp1_vdd_3v3 {
		compatible = "regulator-fixed";
		regulator-name = "vdd-3v3";
		regulator-min-microvolt = <0x325aa0>;
		regulator-max-microvolt = <0x325aa0>;
		regulator-always-on;
		phandle = <0x48>;
	};

	aliases {
		blconfig = "/reserved-memory/nvram@0";
		blpubkey = "/reserved-memory/nvram@1";
		bluetooth = "/soc/serial@7d50c000/bluetooth";
		console = "/soc/serial@7d001000";
		drm-dsi1 = "/axi/pcie@120000/rp1/dsi@110000";
		drm-dsi2 = "/axi/pcie@120000/rp1/dsi@128000";
		ethernet0 = "/axi/pcie@120000/rp1/ethernet@100000";
		fb = "/soc/fb";
		gpio0 = "/axi/pcie@120000/rp1/gpio@d0000";
		gpio1 = "/soc/gpio@7d508500";
		gpio2 = "/soc/gpio@7d517c00";
		gpio3 = "/soc/pinctrl@7d504100";
		gpio4 = "/soc/pinctrl@7d510700";
		gpiochip0 = "/axi/pcie@120000/rp1/gpio@d0000";
		gpiochip10 = "/soc/gpio@7d508500";
		i2c = "/axi/pcie@120000/rp1/i2c@74000";
		i2c0 = "/axi/pcie@120000/rp1/i2c@70000";
		i2c1 = "/axi/pcie@120000/rp1/i2c@74000";
		i2c10 = "/soc/i2c@7d005600";
		i2c2 = "/axi/pcie@120000/rp1/i2c@78000";
		i2c3 = "/axi/pcie@120000/rp1/i2c@7c000";
		i2c4 = "/axi/pcie@120000/rp1/i2c@80000";
		i2c5 = "/axi/pcie@120000/rp1/i2c@84000";
		i2c6 = "/axi/pcie@120000/rp1/i2c@88000";
		mailbox = "/soc/mailbox@7c013880";
		mmc0 = "/axi/mmc@fff000";
		serial0 = "/axi/pcie@120000/rp1/serial@30000";
		serial1 = "/axi/pcie@120000/rp1/serial@34000";
		serial10 = "/soc/serial@7d001000";
		serial2 = "/axi/pcie@120000/rp1/serial@38000";
		serial3 = "/axi/pcie@120000/rp1/serial@3c000";
		serial4 = "/axi/pcie@120000/rp1/serial@40000";
		spi0 = "/axi/pcie@120000/rp1/spi@50000";
		spi1 = "/axi/pcie@120000/rp1/spi@54000";
		spi10 = "/soc/spi@7d004000";
		spi2 = "/axi/pcie@120000/rp1/spi@58000";
		spi3 = "/axi/pcie@120000/rp1/spi@5c000";
		spi4 = "/axi/pcie@120000/rp1/spi@60000";
		spi5 = "/axi/pcie@120000/rp1/spi@64000";
		uart0 = "/axi/pcie@120000/rp1/serial@30000";
		uart1 = "/axi/pcie@120000/rp1/serial@34000";
		uart10 = "/soc/serial@7d001000";
		uart2 = "/axi/pcie@120000/rp1/serial@38000";
		uart3 = "/axi/pcie@120000/rp1/serial@3c000";
		uart4 = "/axi/pcie@120000/rp1/serial@40000";
		usb0 = "/axi/pcie@120000/rp1/usb@200000";
		usb1 = "/axi/pcie@120000/rp1/usb@300000";
		wifi0 = "/axi/mmc@1100000/wifi@1";
		phandle = <0x63>;
	};

	__overrides__ {
		act_led_gpio = [00 00 00 5e 67 70 69 6f 73 3a 34 00 00 00 00 5e 67 70 69 6f 73 3a 30 3d 00 00 00 00 38];
		act_led_activelow = "", "", "", "^gpios:8";
		act_led_trigger = "", "", "", "^linux,default-trigger";
		axiperf = "", "", "", "_status";
		bdaddr = "", "", "", "`local-bd-address[";
		button_debounce = "", "", "", "adebounce-interval:0";
		cooling_fan = [00 00 00 04 73 74 61 74 75 73 00 00 00 00 62 73 74 61 74 75 73 00];
		drm_fb0_rp1_dpi = "", "", "", "cdrm-fb0=", "/axi/pcie@120000/rp1/dpi@148000";
		drm_fb0_rp1_dsi0 = "", "", "", "cdrm-fb0=", "/axi/pcie@120000/rp1/dsi@110000";
		drm_fb0_rp1_dsi1 = "", "", "", "cdrm-fb0=", "/axi/pcie@120000/rp1/dsi@128000";
		drm_fb0_vc4 = "", "", "", "cdrm-fb0=", "/axi/gpu";
		drm_fb1_rp1_dpi = "", "", "", "cdrm-fb1=", "/axi/pcie@120000/rp1/dpi@148000";
		drm_fb1_rp1_dsi0 = "", "", "", "cdrm-fb1=", "/axi/pcie@120000/rp1/dsi@110000";
		drm_fb1_rp1_dsi1 = "", "", "", "cdrm-fb1=", "/axi/pcie@120000/rp1/dsi@128000";
		drm_fb1_vc4 = "", "", "", "cdrm-fb1=", "/axi/gpu";
		drm_fb2_rp1_dpi = "", "", "", "cdrm-fb2=", "/axi/pcie@120000/rp1/dpi@148000";
		drm_fb2_rp1_dsi0 = "", "", "", "cdrm-fb2=", "/axi/pcie@120000/rp1/dsi@110000";
		drm_fb2_rp1_dsi1 = "", "", "", "cdrm-fb2=", "/axi/pcie@120000/rp1/dsi@128000";
		drm_fb2_vc4 = "", "", "", "cdrm-fb2=", "/axi/gpu";
		eth_led0 = "", "", "", "Kled-modes:0";
		eth_led1 = "", "", "", "Kled-modes:4";
		fan_temp0 = [00 00 00 03 74 65 6d 70 65 72 61 74 75 72 65 3a 30 00];
		fan_temp0_hyst = [00 00 00 03 68 79 73 74 65 72 65 73 69 73 3a 30 00];
		fan_temp0_speed = [00 00 00 04 63 6f 6f 6c 69 6e 67 2d 6c 65 76 65 6c 73 3a 34 00];
		fan_temp1 = [00 00 00 05 74 65 6d 70 65 72 61 74 75 72 65 3a 30 00];
		fan_temp1_hyst = [00 00 00 05 68 79 73 74 65 72 65 73 69 73 3a 30 00];
		fan_temp1_speed = [00 00 00 04 63 6f 6f 6c 69 6e 67 2d 6c 65 76 65 6c 73 3a 38 00];
		fan_temp2 = [00 00 00 06 74 65 6d 70 65 72 61 74 75 72 65 3a 30 00];
		fan_temp2_hyst = [00 00 00 06 68 79 73 74 65 72 65 73 69 73 3a 30 00];
		fan_temp2_speed = [00 00 00 04 63 6f 6f 6c 69 6e 67 2d 6c 65 76 65 6c 73 3a 31 32 00];
		fan_temp3 = "", "", "", "\atemperature:0";
		fan_temp3_hyst = "", "", "", "\ahysteresis:0";
		fan_temp3_speed = [00 00 00 04 63 6f 6f 6c 69 6e 67 2d 6c 65 76 65 6c 73 3a 31 36 00];
		i2c = "", "", "", "dstatus";
		i2c_arm = "", "", "", "dstatus";
		i2c_arm_baudrate = "", "", "", "dclock-frequency:0";
		i2c_baudrate = "", "", "", "dclock-frequency:0";
		i2c_csi_dsi = "", "", "", "estatus";
		i2c_csi_dsi0 = "", "", "", "fstatus";
		i2c_csi_dsi1 = "", "", "", "estatus";
		i2c_vc = "", "", "", "gstatus";
		i2c_vc_baudrate = "", "", "", "gclock-frequency:0";
		i2c0 = "", "", "", "gstatus";
		i2c0_baudrate = "", "", "", "gclock-frequency:0";
		i2c1 = "", "", "", "dstatus";
		i2c1_baudrate = "", "", "", "dclock-frequency:0";
		krnbt = "", "", "", "`status";
		nvme = "", "", "", "hstatus";
		nvmem_cust_rw = "", "", "", "irw?";
		nvmem_mac_rw = "", "", "", "jrw?";
		nvmem_priv_rw = "", "", "", "krw?";
		pcie_tperst_clk_ms = "", "", "", "hbrcm,tperst-clk-ms:0";
		pciex1 = "", "", "", "hstatus";
		pciex1_gen = "", "", "", "hmax-link-speed:0";
		pciex1_no_l0s = "", "", "", "haspm-no-l0s?";
		pciex1_tperst_clk_ms = "", "", "", "hbrcm,tperst-clk-ms:0";
		pwr_led_gpio = "", "", "", "lgpios:4";
		pwr_led_activelow = "", "", "", "lgpios:8";
		pwr_led_trigger = "", "", "", "llinux,default-trigger";
		random = "", "", "", "mstatus";
		rtc = "", "", "", "nstatus";
		rtc_bbat_vchg = "", "", "", "ntrickle-charge-microvolt:0";
		spi = "", "", "", "ostatus";
		strict_gpiod = "", "", "", "pbootargs=pinctrl_rp1.persist_gpio_outputs=n";
		suspend = "", "", "", "alinux,code:0=205";
		uart0 = "", "", "", "qstatus";
		uart0_console = "", "", "", "qstatus", "", "", "", "cconsole=", "/axi/pcie@120000/rp1/serial@30000";
		wifiaddr = "", "", "", "rlocal-mac-address[";
		cam0_reg = "", "", "", "sstatus";
		cam0_reg_gpio = [00 00 00 73 67 70 69 6f 3a 34 00 00 00 00 73 67 70 69 6f 3a 30 3d 00 00 00 00 38];
		cam1_reg = "", "", "", "tstatus";
		cam1_reg_gpio = [00 00 00 74 67 70 69 6f 3a 34 00 00 00 00 74 67 70 69 6f 3a 30 3d 00 00 00 00 38];
		sd_cqe = "", "", "", "usupports-cqe?";
	};

	chosen {
		bootargs = "reboot=w coherent_pool=1M 8250.nr_uarts=1 pci=pcie_bus_safe";
		stdout-path = "serial10:115200n8";
		phandle = <0x70>;
	};

	cooling_fan {
		status = "disabled";
		compatible = "pwm-fan";
		#cooling-cells = <0x02>;
		cooling-min-state = <0x00>;
		cooling-max-state = <0x03>;
		cooling-levels = <0x00 0x4b 0x7d 0xaf 0xfa>;
		pwms = <0x62 0x03 0xa25e 0x01>;
		rpm-regmap = <0x62>;
		rpm-offset = <0x3c>;
		phandle = <0x04>;
	};

	pwr_button {
		compatible = "gpio-keys";
		pinctrl-names = "default";
		pinctrl-0 = <0x76>;
		status = "okay";

		pwr {
			label = "pwr_button";
			linux,code = <0x74>;
			gpios = <0x11 0x14 0x01>;
			debounce-interval = <0x32>;
			phandle = <0x61>;
		};
	};

	__symbols__ {
		rmem = "/reserved-memory";
		cma = "/reserved-memory/linux,cma";
		blconfig = "/reserved-memory/nvram@0";
		blpubkey = "/reserved-memory/nvram@1";
		cpu_thermal = "/thermal-zones/cpu-thermal";
		thermal_trips = "/thermal-zones/cpu-thermal/trips";
		cpu_crit = "/thermal-zones/cpu-thermal/trips/cpu-crit";
		cpu_tepid = "/thermal-zones/cpu-thermal/trips/cpu-tepid";
		cpu_warm = "/thermal-zones/cpu-thermal/trips/cpu-warm";
		cpu_hot = "/thermal-zones/cpu-thermal/trips/cpu-hot";
		cpu_vhot = "/thermal-zones/cpu-thermal/trips/cpu-vhot";
		cooling_maps = "/thermal-zones/cpu-thermal/cooling-maps";
		clk_27MHz = "/clk-27M";
		clk_108MHz = "/clk-108M";
		hvs = "/hvs@107c580000";
		soc = "/soc";
		system_timer = "/soc/timer@7c003000";
		firmwarekms = "/soc/firmwarekms@7d503000";
		axiperf = "/soc/axiperf";
		mailbox = "/soc/mailbox@7c013880";
		pixelvalve0 = "/soc/pixelvalve@7c410000";
		pixelvalve1 = "/soc/pixelvalve@7c411000";
		mop = "/soc/mop@7c500000";
		moplet = "/soc/moplet@7c501000";
		disp_intr = "/soc/interrupt-controller@7c502000";
		dvp = "/soc/clock@7c700000";
		local_intc = "/soc/local_intc@7cd00000";
		uart10 = "/soc/serial@7d001000";
		_uart0 = "/soc/serial@7d001000";
		_uart2 = "/soc/serial@7d001400";
		_uart5 = "/soc/serial@7d001a00";
		sdhost = "/soc/mmc@7d002000";
		_i2s = "/soc/_i2s@7d003000";
		spi10 = "/soc/spi@7d004000";
		_spi0 = "/soc/spi@7d004000";
		spidev10 = "/soc/spi@7d004000/spidev@0";
		_spi3 = "/soc/spi@7d004600";
		_spi4 = "/soc/spi@7d004800";
		_spi5 = "/soc/spi@7d004a00";
		_spi6 = "/soc/spi@7d004c00";
		_i2c0 = "/soc/i2c@7d005000";
		i2c_rp1boot = "/soc/i2c@7d005600";
		_i2c3 = "/soc/i2c@7d005600";
		_i2c4 = "/soc/i2c@7d005800";
		_i2c5 = "/soc/i2c@7d005a00";
		_i2c6 = "/soc/i2c@7d005c00";
		_i2c8 = "/soc/i2c@7d005e00";
		_pwm0 = "/soc/pwm@7d00c000";
		_pwm1 = "/soc/pwm@7d00c800";
		pm = "/soc/watchdog@7d200000";
		cprman = "/soc/cprman@7d202000";
		random = "/soc/rng@7d208000";
		cpu_l2_irq = "/soc/intc@7d503000";
		pinctrl = "/soc/pinctrl@7d504100";
		uarta_24_pins = "/soc/pinctrl@7d504100/uarta_24_pins";
		sdio2_30_pins = "/soc/pinctrl@7d504100/sdio2_30_pins";
		pwr_button_pins = "/soc/pinctrl@7d504100/pwr_button_pins";
		wl_on_pins = "/soc/pinctrl@7d504100/wl_on_pins";
		bt_shutdown_pins = "/soc/pinctrl@7d504100/bt_shutdown_pins";
		emmc_sd_pulls = "/soc/pinctrl@7d504100/emmc_sd_pulls";
		spi10_pins = "/soc/pinctrl@7d504100/spi10_gpio2";
		spi10_gpio2 = "/soc/pinctrl@7d504100/spi10_gpio2";
		spi10_cs_pins = "/soc/pinctrl@7d504100/spi10_cs_gpio1";
		spi10_cs_gpio1 = "/soc/pinctrl@7d504100/spi10_cs_gpio1";
		ddc0 = "/soc/i2c@7d508200";
		ddc1 = "/soc/i2c@7d508280";
		bscd = "/soc/i2c@7d508300";
		bsc_irq = "/soc/intc@7d508380";
		main_irq = "/soc/intc@7d508400";
		gio = "/soc/gpio@7d508500";
		uarta = "/soc/serial@7d50c000";
		bluetooth = "/soc/serial@7d50c000/bluetooth";
		uartb = "/soc/serial@7d50d000";
		aon_intr = "/soc/interrupt-controller@7d510600";
		pinctrl_aon = "/soc/pinctrl@7d510700";
		i2c3_m4_agpio0_pins = "/soc/pinctrl@7d510700/i2c3_m4_agpio0_pins";
		bsc_m1_agpio13_pins = "/soc/pinctrl@7d510700/bsc_m1_agpio13_pins";
		bsc_pmu_sgpio4_pins = "/soc/pinctrl@7d510700/bsc_pmu_sgpio4_pins";
		bsc_m2_sgpio4_pins = "/soc/pinctrl@7d510700/bsc_m2_sgpio4_pins";
		pwm_aon_agpio1_pins = "/soc/pinctrl@7d510700/pwm_aon_agpio1_pins";
		pwm_aon_agpio4_pins = "/soc/pinctrl@7d510700/pwm_aon_agpio4_pins";
		pwm_aon_agpio7_pins = "/soc/pinctrl@7d510700/pwm_aon_agpio7_pins";
		emmc_aon_cd_pins = "/soc/pinctrl@7d510700/emmc_aon_cd_pins";
		aon_pwm_1pin = "/soc/pinctrl@7d510700/aon_pwm_1pin";
		bscc = "/soc/i2c@7d517a00";
		pwm_aon = "/soc/pwm@7d517a80";
		main_aon_irq = "/soc/intc@7d517ac0";
		bsc_aon_irq = "/soc/intc@7d517b00";
		gio_aon = "/soc/gpio@7d517c00";
		avs_monitor = "/soc/avs-monitor@7d542000";
		thermal = "/soc/avs-monitor@7d542000/thermal";
		bsc_pmu = "/soc/i2c@7d544000";
		hdmi0 = "/soc/hdmi@7ef00700";
		hdmi1 = "/soc/hdmi@7ef05700";
		firmware = "/soc/firmware";
		firmware_clocks = "/soc/firmware/clocks";
		reset = "/soc/firmware/reset";
		vcio = "/soc/firmware/vcio";
		power = "/soc/power";
		fb = "/soc/fb";
		rpi_rtc = "/soc/rpi_rtc";
		nvmem_otp = "/soc/nvmem/nvmem_otp";
		nvmem_cust = "/soc/nvmem/nvmem_cust";
		nvmem_mac = "/soc/nvmem/nvmem_mac";
		nvmem_priv = "/soc/nvmem/nvmem_priv";
		vdd_3v3_reg = "/soc/fixedregulator_3v3";
		vdd_5v0_reg = "/soc/fixedregulator_5v0";
		sound = "/soc/sound";
		cpus = "/cpus";
		cpu0 = "/cpus/cpu@0";
		cpu1 = "/cpus/cpu@1";
		cpu2 = "/cpus/cpu@2";
		cpu3 = "/cpus/cpu@3";
		l2_cache_l0 = "/cpus/l2-cache-l0";
		l2_cache_l1 = "/cpus/l2-cache-l1";
		l2_cache_l2 = "/cpus/l2-cache-l2";
		l2_cache_l3 = "/cpus/l2-cache-l3";
		l3_cache = "/cpus/l3-cache";
		axi = "/axi";
		vc4 = "/axi/gpu";
		iommu2 = "/axi/iommu@5100";
		iommu4 = "/axi/iommu@5200";
		iommu5 = "/axi/iommu@5280";
		iommuc = "/axi/iommuc@5b00";
		dma32 = "/axi/dma@10000";
		dma40 = "/axi/dma@10600";
		pcie0 = "/axi/pcie@100000";
		pciex1 = "/axi/pcie@110000";
		pcie1 = "/axi/pcie@110000";
		pcie_rescal = "/axi/reset-controller@119500";
		pciex4 = "/axi/pcie@120000";
		rp1_target = "/axi/pcie@120000";
		pcie2 = "/axi/pcie@120000";
		rp1 = "/axi/pcie@120000/rp1";
		rp1_clocks = "/axi/pcie@120000/rp1/clocks@18000";
		uart0 = "/axi/pcie@120000/rp1/serial@30000";
		rp1_uart0 = "/axi/pcie@120000/rp1/serial@30000";
		uart1 = "/axi/pcie@120000/rp1/serial@34000";
		rp1_uart1 = "/axi/pcie@120000/rp1/serial@34000";
		uart2 = "/axi/pcie@120000/rp1/serial@38000";
		rp1_uart2 = "/axi/pcie@120000/rp1/serial@38000";
		uart3 = "/axi/pcie@120000/rp1/serial@3c000";
		rp1_uart3 = "/axi/pcie@120000/rp1/serial@3c000";
		uart4 = "/axi/pcie@120000/rp1/serial@40000";
		rp1_uart4 = "/axi/pcie@120000/rp1/serial@40000";
		rp1_uart5 = "/axi/pcie@120000/rp1/serial@44000";
		rp1_spi8 = "/axi/pcie@120000/rp1/spi@4c000";
		spi0 = "/axi/pcie@120000/rp1/spi@50000";
		rp1_spi0 = "/axi/pcie@120000/rp1/spi@50000";
		spidev0 = "/axi/pcie@120000/rp1/spi@50000/spidev@0";
		spidev1 = "/axi/pcie@120000/rp1/spi@50000/spidev@1";
		spi1 = "/axi/pcie@120000/rp1/spi@54000";
		rp1_spi1 = "/axi/pcie@120000/rp1/spi@54000";
		spi2 = "/axi/pcie@120000/rp1/spi@58000";
		rp1_spi2 = "/axi/pcie@120000/rp1/spi@58000";
		spi3 = "/axi/pcie@120000/rp1/spi@5c000";
		rp1_spi3 = "/axi/pcie@120000/rp1/spi@5c000";
		spi4 = "/axi/pcie@120000/rp1/spi@60000";
		rp1_spi4 = "/axi/pcie@120000/rp1/spi@60000";
		spi5 = "/axi/pcie@120000/rp1/spi@64000";
		rp1_spi5 = "/axi/pcie@120000/rp1/spi@64000";
		rp1_spi6 = "/axi/pcie@120000/rp1/spi@68000";
		rp1_spi7 = "/axi/pcie@120000/rp1/spi@6c000";
		i2c_vc = "/axi/pcie@120000/rp1/i2c@70000";
		i2c0 = "/axi/pcie@120000/rp1/i2c@70000";
		rp1_i2c0 = "/axi/pcie@120000/rp1/i2c@70000";
		i2c_arm = "/axi/pcie@120000/rp1/i2c@74000";
		i2c1 = "/axi/pcie@120000/rp1/i2c@74000";
		rp1_i2c1 = "/axi/pcie@120000/rp1/i2c@74000";
		i2c2 = "/axi/pcie@120000/rp1/i2c@78000";
		rp1_i2c2 = "/axi/pcie@120000/rp1/i2c@78000";
		i2c3 = "/axi/pcie@120000/rp1/i2c@7c000";
		rp1_i2c3 = "/axi/pcie@120000/rp1/i2c@7c000";
		i2c_csi_dsi = "/axi/pcie@120000/rp1/i2c@80000";
		i2c_csi_dsi1 = "/axi/pcie@120000/rp1/i2c@80000";
		i2c4 = "/axi/pcie@120000/rp1/i2c@80000";
		rp1_i2c4 = "/axi/pcie@120000/rp1/i2c@80000";
		i2c5 = "/axi/pcie@120000/rp1/i2c@84000";
		rp1_i2c5 = "/axi/pcie@120000/rp1/i2c@84000";
		i2c_csi_dsi0 = "/axi/pcie@120000/rp1/i2c@88000";
		i2c6 = "/axi/pcie@120000/rp1/i2c@88000";
		rp1_i2c6 = "/axi/pcie@120000/rp1/i2c@88000";
		pwm = "/axi/pcie@120000/rp1/pwm@98000";
		pwm0 = "/axi/pcie@120000/rp1/pwm@98000";
		rp1_pwm0 = "/axi/pcie@120000/rp1/pwm@98000";
		pwm1 = "/axi/pcie@120000/rp1/pwm@9c000";
		rp1_pwm1 = "/axi/pcie@120000/rp1/pwm@9c000";
		i2s_clk_producer = "/axi/pcie@120000/rp1/i2s@a0000";
		i2s = "/axi/pcie@120000/rp1/i2s@a0000";
		rp1_i2s0 = "/axi/pcie@120000/rp1/i2s@a0000";
		i2s_clk_consumer = "/axi/pcie@120000/rp1/i2s@a4000";
		rp1_i2s1 = "/axi/pcie@120000/rp1/i2s@a4000";
		rp1_i2s2 = "/axi/pcie@120000/rp1/i2s@a8000";
		rp1_sdio_clk0 = "/axi/pcie@120000/rp1/sdio_clk0@b0004";
		rp1_sdio_clk1 = "/axi/pcie@120000/rp1/sdio_clk1@b4004";
		rp1_adc = "/axi/pcie@120000/rp1/adc@c8000";
		gpio = "/axi/pcie@120000/rp1/gpio@d0000";
		rp1_gpio = "/axi/pcie@120000/rp1/gpio@d0000";
		uart0_pins = "/axi/pcie@120000/rp1/gpio@d0000/rp1_uart0_14_15";
		rp1_uart0_14_15 = "/axi/pcie@120000/rp1/gpio@d0000/rp1_uart0_14_15";
		uart0_ctsrts_pins = "/axi/pcie@120000/rp1/gpio@d0000/rp1_uart0_ctsrts_16_17";
		rp1_uart0_ctsrts_16_17 = "/axi/pcie@120000/rp1/gpio@d0000/rp1_uart0_ctsrts_16_17";
		uart1_pins = "/axi/pcie@120000/rp1/gpio@d0000/rp1_uart1_0_1";
		rp1_uart1_0_1 = "/axi/pcie@120000/rp1/gpio@d0000/rp1_uart1_0_1";
		uart1_ctsrts_pins = "/axi/pcie@120000/rp1/gpio@d0000/rp1_uart1_ctsrts_2_3";
		rp1_uart1_ctsrts_2_3 = "/axi/pcie@120000/rp1/gpio@d0000/rp1_uart1_ctsrts_2_3";
		uart2_pins = "/axi/pcie@120000/rp1/gpio@d0000/rp1_uart2_4_5";
		rp1_uart2_4_5 = "/axi/pcie@120000/rp1/gpio@d0000/rp1_uart2_4_5";
		uart2_ctsrts_pins = "/axi/pcie@120000/rp1/gpio@d0000/rp1_uart2_ctsrts_6_7";
		rp1_uart2_ctsrts_6_7 = "/axi/pcie@120000/rp1/gpio@d0000/rp1_uart2_ctsrts_6_7";
		uart3_pins = "/axi/pcie@120000/rp1/gpio@d0000/rp1_uart3_8_9";
		rp1_uart3_8_9 = "/axi/pcie@120000/rp1/gpio@d0000/rp1_uart3_8_9";
		uart3_ctsrts_pins = "/axi/pcie@120000/rp1/gpio@d0000/rp1_uart3_ctsrts_10_11";
		rp1_uart3_ctsrts_10_11 = "/axi/pcie@120000/rp1/gpio@d0000/rp1_uart3_ctsrts_10_11";
		uart4_pins = "/axi/pcie@120000/rp1/gpio@d0000/rp1_uart4_12_13";
		rp1_uart4_12_13 = "/axi/pcie@120000/rp1/gpio@d0000/rp1_uart4_12_13";
		uart4_ctsrts_pins = "/axi/pcie@120000/rp1/gpio@d0000/rp1_uart4_ctsrts_14_15";
		rp1_uart4_ctsrts_14_15 = "/axi/pcie@120000/rp1/gpio@d0000/rp1_uart4_ctsrts_14_15";
		rp1_sdio0_22_27 = "/axi/pcie@120000/rp1/gpio@d0000/rp1_sdio0_22_27";
		rp1_sdio1_28_33 = "/axi/pcie@120000/rp1/gpio@d0000/rp1_sdio1_28_33";
		rp1_i2s0_18_21 = "/axi/pcie@120000/rp1/gpio@d0000/rp1_i2s0_18_21";
		rp1_i2s1_18_21 = "/axi/pcie@120000/rp1/gpio@d0000/rp1_i2s1_18_21";
		rp1_i2c4_34_35 = "/axi/pcie@120000/rp1/gpio@d0000/rp1_i2c4_34_35";
		rp1_i2c6_38_39 = "/axi/pcie@120000/rp1/gpio@d0000/rp1_i2c6_38_39";
		rp1_i2c4_40_41 = "/axi/pcie@120000/rp1/gpio@d0000/rp1_i2c4_40_41";
		rp1_i2c5_44_45 = "/axi/pcie@120000/rp1/gpio@d0000/rp1_i2c5_44_45";
		i2c0_pins = "/axi/pcie@120000/rp1/gpio@d0000/rp1_i2c0_0_1";
		rp1_i2c0_0_1 = "/axi/pcie@120000/rp1/gpio@d0000/rp1_i2c0_0_1";
		rp1_i2c0_8_9 = "/axi/pcie@120000/rp1/gpio@d0000/rp1_i2c0_8_9";
		i2c1_pins = "/axi/pcie@120000/rp1/gpio@d0000/rp1_i2c1_2_3";
		rp1_i2c1_2_3 = "/axi/pcie@120000/rp1/gpio@d0000/rp1_i2c1_2_3";
		rp1_i2c1_10_11 = "/axi/pcie@120000/rp1/gpio@d0000/rp1_i2c1_10_11";
		i2c2_pins = "/axi/pcie@120000/rp1/gpio@d0000/rp1_i2c2_4_5";
		rp1_i2c2_4_5 = "/axi/pcie@120000/rp1/gpio@d0000/rp1_i2c2_4_5";
		rp1_i2c2_12_13 = "/axi/pcie@120000/rp1/gpio@d0000/rp1_i2c2_12_13";
		i2c3_pins = "/axi/pcie@120000/rp1/gpio@d0000/rp1_i2c3_6_7";
		rp1_i2c3_6_7 = "/axi/pcie@120000/rp1/gpio@d0000/rp1_i2c3_6_7";
		rp1_i2c3_14_15 = "/axi/pcie@120000/rp1/gpio@d0000/rp1_i2c3_14_15";
		rp1_i2c3_22_23 = "/axi/pcie@120000/rp1/gpio@d0000/rp1_i2c3_22_23";
		dpi_16bit_gpio2 = "/axi/pcie@120000/rp1/gpio@d0000/rp1_dpi_16bit_gpio2";
		rp1_dpi_16bit_gpio2 = "/axi/pcie@120000/rp1/gpio@d0000/rp1_dpi_16bit_gpio2";
		dpi_16bit_cpadhi_gpio2 = "/axi/pcie@120000/rp1/gpio@d0000/rp1_dpi_16bit_cpadhi_gpio2";
		rp1_dpi_16bit_cpadhi_gpio2 = "/axi/pcie@120000/rp1/gpio@d0000/rp1_dpi_16bit_cpadhi_gpio2";
		rp1_dpi_16bit_pad666_gpio2 = "/axi/pcie@120000/rp1/gpio@d0000/rp1_dpi_16bit_pad666_gpio2";
		dpi_18bit_gpio2 = "/axi/pcie@120000/rp1/gpio@d0000/rp1_dpi_18bit_gpio2";
		rp1_dpi_18bit_gpio2 = "/axi/pcie@120000/rp1/gpio@d0000/rp1_dpi_18bit_gpio2";
		dpi_18bit_cpadhi_gpio2 = "/axi/pcie@120000/rp1/gpio@d0000/rp1_dpi_18bit_cpadhi_gpio2";
		rp1_dpi_18bit_cpadhi_gpio2 = "/axi/pcie@120000/rp1/gpio@d0000/rp1_dpi_18bit_cpadhi_gpio2";
		dpi_gpio1 = "/axi/pcie@120000/rp1/gpio@d0000/rp1_dpi_24bit_gpio2";
		rp1_dpi_24bit_gpio2 = "/axi/pcie@120000/rp1/gpio@d0000/rp1_dpi_24bit_gpio2";
		rp1_dpi_hvsync = "/axi/pcie@120000/rp1/gpio@d0000/rp1_dpi_hvsync";
		dpi_16bit_gpio0 = "/axi/pcie@120000/rp1/gpio@d0000/rp1_dpi_16bit_gpio0";
		rp1_dpi_16bit_gpio0 = "/axi/pcie@120000/rp1/gpio@d0000/rp1_dpi_16bit_gpio0";
		dpi_16bit_cpadhi_gpio0 = "/axi/pcie@120000/rp1/gpio@d0000/rp1_dpi_16bit_cpadhi_gpio0";
		rp1_dpi_16bit_cpadhi_gpio0 = "/axi/pcie@120000/rp1/gpio@d0000/rp1_dpi_16bit_cpadhi_gpio0";
		rp1_dpi_16bit_pad666_gpio0 = "/axi/pcie@120000/rp1/gpio@d0000/rp1_dpi_16bit_pad666_gpio0";
		dpi_18bit_gpio0 = "/axi/pcie@120000/rp1/gpio@d0000/rp1_dpi_18bit_gpio0";
		rp1_dpi_18bit_gpio0 = "/axi/pcie@120000/rp1/gpio@d0000/rp1_dpi_18bit_gpio0";
		dpi_18bit_cpadhi_gpio0 = "/axi/pcie@120000/rp1/gpio@d0000/rp1_dpi_18bit_cpadhi_gpio0";
		rp1_dpi_18bit_cpadhi_gpio0 = "/axi/pcie@120000/rp1/gpio@d0000/rp1_dpi_18bit_cpadhi_gpio0";
		dpi_gpio0 = "/axi/pcie@120000/rp1/gpio@d0000/rp1_dpi_24bit_gpio0";
		rp1_dpi_24bit_gpio0 = "/axi/pcie@120000/rp1/gpio@d0000/rp1_dpi_24bit_gpio0";
		rp1_gpclksrc0_gpio4 = "/axi/pcie@120000/rp1/gpio@d0000/rp1_gpclksrc0_gpio4";
		rp1_gpclksrc0_gpio20 = "/axi/pcie@120000/rp1/gpio@d0000/rp1_gpclksrc0_gpio20";
		rp1_gpclksrc1_gpio5 = "/axi/pcie@120000/rp1/gpio@d0000/rp1_gpclksrc1_gpio5";
		rp1_gpclksrc1_gpio18 = "/axi/pcie@120000/rp1/gpio@d0000/rp1_gpclksrc1_gpio18";
		rp1_gpclksrc1_gpio21 = "/axi/pcie@120000/rp1/gpio@d0000/rp1_gpclksrc1_gpio21";
		rp1_pwm1_gpio45 = "/axi/pcie@120000/rp1/gpio@d0000/rp1_pwm1_gpio45";
		spi0_pins = "/axi/pcie@120000/rp1/gpio@d0000/rp1_spi0_gpio9";
		rp1_spi0_gpio9 = "/axi/pcie@120000/rp1/gpio@d0000/rp1_spi0_gpio9";
		spi0_cs_pins = "/axi/pcie@120000/rp1/gpio@d0000/rp1_spi0_cs_gpio7";
		rp1_spi0_cs_gpio7 = "/axi/pcie@120000/rp1/gpio@d0000/rp1_spi0_cs_gpio7";
		rp1_spi1_gpio19 = "/axi/pcie@120000/rp1/gpio@d0000/rp1_spi1_gpio19";
		spi2_pins = "/axi/pcie@120000/rp1/gpio@d0000/rp1_spi2_gpio1";
		rp1_spi2_gpio1 = "/axi/pcie@120000/rp1/gpio@d0000/rp1_spi2_gpio1";
		spi3_pins = "/axi/pcie@120000/rp1/gpio@d0000/rp1_spi3_gpio5";
		rp1_spi3_gpio5 = "/axi/pcie@120000/rp1/gpio@d0000/rp1_spi3_gpio5";
		spi4_pins = "/axi/pcie@120000/rp1/gpio@d0000/rp1_spi4_gpio9";
		rp1_spi4_gpio9 = "/axi/pcie@120000/rp1/gpio@d0000/rp1_spi4_gpio9";
		spi5_pins = "/axi/pcie@120000/rp1/gpio@d0000/rp1_spi5_gpio13";
		rp1_spi5_gpio13 = "/axi/pcie@120000/rp1/gpio@d0000/rp1_spi5_gpio13";
		rp1_spi8_gpio49 = "/axi/pcie@120000/rp1/gpio@d0000/rp1_spi8_gpio49";
		rp1_spi8_cs_gpio52 = "/axi/pcie@120000/rp1/gpio@d0000/rp1_spi8_cs_gpio52";
		usb_vbus_pins = "/axi/pcie@120000/rp1/gpio@d0000/usb_vbus_pins";
		rp1_eth = "/axi/pcie@120000/rp1/ethernet@100000";
		phy1 = "/axi/pcie@120000/rp1/ethernet@100000/ethernet-phy@1";
		csi0 = "/axi/pcie@120000/rp1/csi@110000";
		rp1_csi0 = "/axi/pcie@120000/rp1/csi@110000";
		csi1 = "/axi/pcie@120000/rp1/csi@128000";
		rp1_csi1 = "/axi/pcie@120000/rp1/csi@128000";
		rp1_mmc0 = "/axi/pcie@120000/rp1/mmc@180000";
		rp1_mmc1 = "/axi/pcie@120000/rp1/mmc@184000";
		rp1_dma = "/axi/pcie@120000/rp1/dma@188000";
		rp1_usb0 = "/axi/pcie@120000/rp1/usb@200000";
		rp1_usb1 = "/axi/pcie@120000/rp1/usb@300000";
		dsi0 = "/axi/pcie@120000/rp1/dsi@110000";
		rp1_dsi0 = "/axi/pcie@120000/rp1/dsi@110000";
		dsi1 = "/axi/pcie@120000/rp1/dsi@128000";
		rp1_dsi1 = "/axi/pcie@120000/rp1/dsi@128000";
		vec = "/axi/pcie@120000/rp1/vec@144000";
		rp1_vec = "/axi/pcie@120000/rp1/vec@144000";
		dpi = "/axi/pcie@120000/rp1/dpi@148000";
		rp1_dpi = "/axi/pcie@120000/rp1/dpi@148000";
		mip0 = "/axi/msi-controller@130000";
		mip1 = "/axi/msi-controller@131000";
		syscon_piarbctl = "/axi/syscon@400018";
		usb = "/axi/usb@480000";
		rpivid = "/axi/codec@800000";
		sdio1 = "/axi/mmc@fff000";
		sdio2 = "/axi/mmc@1100000";
		wifi = "/axi/mmc@1100000/wifi@1";
		bcm_reset = "/axi/reset-controller@1504318";
		v3d = "/axi/v3d@2000000";
		gicv2 = "/axi/interrupt-controller@7fff9000";
		pisp_be = "/axi/pisp_be@880000";
		clocks = "/clocks";
		clk_osc = "/clocks/clk-osc";
		clk_usb = "/clocks/clk-usb";
		clk_vpu = "/clocks/clk_vpu";
		clk_uart = "/clocks/clk_uart";
		clk_emmc2 = "/clocks/clk_emmc2";
		clk_xosc = "/clocks/clk_xosc";
		macb_pclk = "/clocks/macb_pclk";
		macb_hclk = "/clocks/macb_hclk";
		sdio_src = "/clocks/sdio_src";
		sdhci_core = "/clocks/sdhci_core";
		clksrc_gp0 = "/clocks/clksrc_gp0";
		clksrc_gp1 = "/clocks/clksrc_gp1";
		clksrc_gp2 = "/clocks/clksrc_gp2";
		clksrc_gp3 = "/clocks/clksrc_gp3";
		clksrc_gp4 = "/clocks/clksrc_gp4";
		clksrc_gp5 = "/clocks/clksrc_gp5";
		usbphy = "/phy";
		leds = "/leds";
		led_pwr = "/leds/led-pwr";
		led_act = "/leds/led-act";
		sd_io_1v8_reg = "/sd_io_1v8_reg";
		sd_vcc_reg = "/sd_vcc_reg";
		wl_on_reg = "/wl_on_reg";
		cam1_clk = "/cam1_clk";
		cam0_clk = "/cam0_clk";
		cam0_reg = "/cam0_reg";
		cam1_reg = "/cam1_reg";
		cam_dummy_reg = "/cam_dummy_reg";
		aux = "/dummy";
		dummy = "/dummy";
		i2c0if = "/i2c0if";
		i2c0mux = "/i2c0mux";
		rp1_vdd_3v3 = "/rp1_vdd_3v3";
		aliases = "/aliases";
		chosen = "/chosen";
		fan = "/cooling_fan";
		pwr_key = "/pwr_button/pwr";
	};
};
